VERSION "HNPBNYYYYYYYYYYYYYYYYYYYYYYYYYYYNNNNNNNNNN/4/%%%/4/'%**4NNN///"
NS_ :

BS_:

BU_: BDC546 imc_BUSFX_2_133754 Sender__XXX WC HC0 HC1 HC2 HC3 Xsens_Sensor

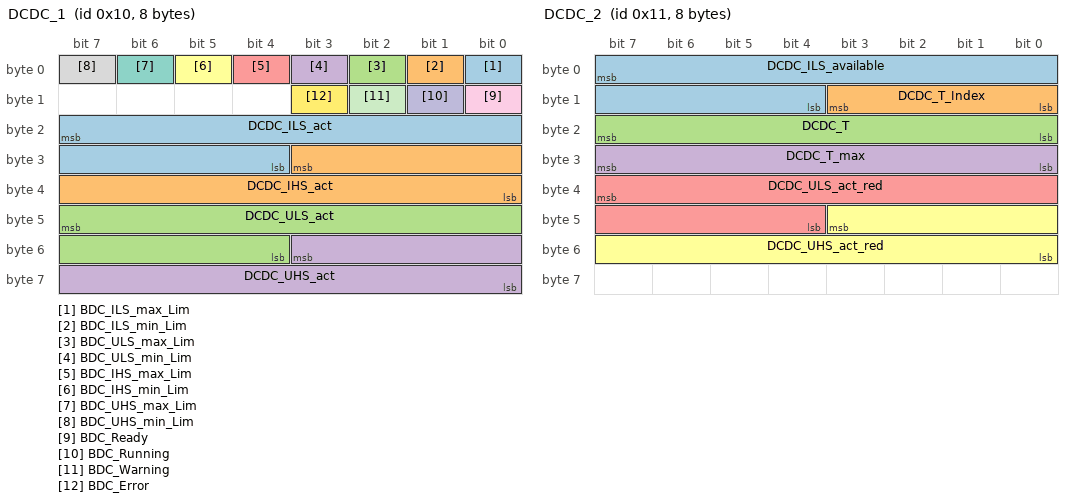
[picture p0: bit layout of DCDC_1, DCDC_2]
BO_ 16 DCDC_1: 8 BDC546
 SG_ BDC_ILS_max_Lim : 0|1@1+ (1,0) [0|1] ""  imc_BUSFX_2_133754
 SG_ BDC_ILS_min_Lim : 1|1@1+ (1,0) [0|1] ""  imc_BUSFX_2_133754
 SG_ BDC_ULS_max_Lim : 2|1@1+ (1,0) [0|1] ""  imc_BUSFX_2_133754
 SG_ BDC_ULS_min_Lim : 3|1@1+ (1,0) [0|1] ""  imc_BUSFX_2_133754
 SG_ BDC_IHS_max_Lim : 4|1@1+ (1,0) [0|1] ""  imc_BUSFX_2_133754
 SG_ BDC_IHS_min_Lim : 5|1@1+ (1,0) [0|1] ""  imc_BUSFX_2_133754
 SG_ BDC_UHS_max_Lim : 6|1@1+ (1,0) [0|1] ""  imc_BUSFX_2_133754
 SG_ BDC_UHS_min_Lim : 7|1@1+ (1,0) [0|1] ""  imc_BUSFX_2_133754
 SG_ BDC_Ready : 8|1@1+ (1,0) [0|1] ""  imc_BUSFX_2_133754
 SG_ BDC_Running : 9|1@1+ (1,0) [0|1] ""  imc_BUSFX_2_133754
 SG_ BDC_Warning : 10|1@1+ (1,0) [0|1] ""  imc_BUSFX_2_133754
 SG_ BDC_Error : 11|1@1+ (1,0) [0|1] ""  imc_BUSFX_2_133754
 SG_ DCDC_ILS_act : 23|12@0+ (2.500000000E-1,-5.120000000E+2) [-5.120000000E+2|5.117500000E+2] "A"  imc_BUSFX_2_133754
 SG_ DCDC_IHS_act : 27|12@0+ (2.500000000E-1,-5.120000000E+2) [-5.120000000E+2|5.117500000E+2] "A"  imc_BUSFX_2_133754
 SG_ DCDC_ULS_act : 47|12@0+ (2.500000000E-1,0.000000000E+0) [0.000000000E+0|1.023750000E+3] "V"  imc_BUSFX_2_133754
 SG_ DCDC_UHS_act : 51|12@0+ (2.500000000E-1,0.000000000E+0) [0.000000000E+0|1.023750000E+3] "V"  imc_BUSFX_2_133754

BO_ 17 DCDC_2: 8 BDC546
 SG_ DCDC_ILS_available : 7|12@0+ (2.500000000E-1,0.000000000E+0) [0.000000000E+0|1.023750000E+3] "A"  imc_BUSFX_2_133754
 SG_ DCDC_T_Index : 11|4@0+ (1.000000000E+0,0.000000000E+0) [0.000000000E+0|1.500000000E+1] ""  imc_BUSFX_2_133754
 SG_ DCDC_T : 23|8@0+ (1.000000000E+0,-4.000000000E+1) [-4.000000000E+1|2.150000000E+2] "C"  imc_BUSFX_2_133754
 SG_ DCDC_T_max : 31|8@0+ (1.000000000E+0,-4.000000000E+1) [-4.000000000E+1|2.150000000E+2] "C"  imc_BUSFX_2_133754
 SG_ DCDC_ULS_act_red : 39|12@0+ (2.500000000E-1,0.000000000E+0) [0.000000000E+0|1.023750000E+3] "V"  imc_BUSFX_2_133754
 SG_ DCDC_UHS_act_red : 43|12@0+ (2.500000000E-1,0.000000000E+0) [0.000000000E+0|1.023750000E+3] "V"  imc_BUSFX_2_133754

BO_ 18 DCDC_3: 8 BDC546
 SG_ BDC_Err_RedNegLS : 0|1@1+ (1,0) [0|1] ""  imc_BUSFX_2_133754
 SG_ BDC_Err_RedPosLS : 1|1@1+ (1,0) [0|1] ""  imc_BUSFX_2_133754
 SG_ BDC_Err_PyroMC : 2|1@1+ (1,0) [0|1] ""  imc_BUSFX_2_133754
 SG_ BDC_Err_TempSens : 8|1@1+ (1,0) [0|1] ""  imc_BUSFX_2_133754
 SG_ BDC_Err_Interlock : 9|1@1+ (1,0) [0|1] ""  imc_BUSFX_2_133754
 SG_ BDC_Err_ISensLS : 10|1@1+ (1,0) [0|1] ""  imc_BUSFX_2_133754
 SG_ BDC_Err_ISensHS : 11|1@1+ (1,0) [0|1] ""  imc_BUSFX_2_133754
 SG_ BDC_Err_BDCMode : 12|1@1+ (1,0) [0|1] ""  imc_BUSFX_2_133754
 SG_ BDC_Err_IHS2ILS : 13|1@1+ (1,0) [0|1] ""  imc_BUSFX_2_133754
 SG_ BDC_Err_RedNegHS : 14|1@1+ (1,0) [0|1] ""  imc_BUSFX_2_133754
 SG_ BDC_Err_RedPosHS : 15|1@1+ (1,0) [0|1] ""  imc_BUSFX_2_133754
 SG_ BDC_Err_Timeout_Recv3 : 19|1@1+ (1,0) [0|1] ""  imc_BUSFX_2_133754
 SG_ BDC_Err_Timeout_Recv2 : 20|1@1+ (1,0) [0|1] ""  imc_BUSFX_2_133754
 SG_ BDC_Err_Timeout_Recv1 : 21|1@1+ (1,0) [0|1] ""  imc_BUSFX_2_133754
 SG_ BDC_Err_CANValue : 22|1@1+ (1,0) [0|1] ""  imc_BUSFX_2_133754
 SG_ BDC_Err_IntSupply : 23|1@1+ (1,0) [0|1] ""  imc_BUSFX_2_133754
 SG_ BDC_Err_FPGA : 3|1@1+ (1,0) [0|1] ""  imc_BUSFX_2_133754
 SG_ BDC_Err_NVSRam : 4|1@1+ (1,0) [0|1] ""  imc_BUSFX_2_133754
 SG_ BDC_Err_Flash : 5|1@1+ (1,0) [0|1] ""  imc_BUSFX_2_133754
 SG_ BDC_Err_EEProm : 6|1@1+ (1,0) [0|1] ""  imc_BUSFX_2_133754
 SG_ BDC_Err_HW_FPGA_Ver : 7|1@1+ (1,0) [0|1] ""  imc_BUSFX_2_133754
 SG_ BDC_Err_CANTx : 16|1@1+ (1,0) [0|1] ""  imc_BUSFX_2_133754
 SG_ BDC_Err_CANRx : 17|1@1+ (1,0) [0|1] ""  imc_BUSFX_2_133754
 SG_ BDC_Err_CANOff : 18|1@1+ (1,0) [0|1] ""  imc_BUSFX_2_133754
 SG_ BDC_Err_OvltSky : 29|1@1+ (1,0) [0|1] ""  imc_BUSFX_2_133754
 SG_ BDC_Err_OvltLS : 30|1@1+ (1,0) [0|1] ""  imc_BUSFX_2_133754
 SG_ BDC_Err_OvltHS : 31|1@1+ (1,0) [0|1] ""  imc_BUSFX_2_133754
 SG_ BDC_War_TempIndD : 32|1@1+ (1,0) [0|1] ""  imc_BUSFX_2_133754
 SG_ BDC_War_TempIndC : 33|1@1+ (1,0) [0|1] ""  imc_BUSFX_2_133754
 SG_ BDC_War_TempIndB : 34|1@1+ (1,0) [0|1] ""  imc_BUSFX_2_133754
 SG_ BDC_War_TempIndA : 35|1@1+ (1,0) [0|1] ""  imc_BUSFX_2_133754
 SG_ BDC_War_Reset : 36|1@1+ (1,0) [0|1] ""  imc_BUSFX_2_133754
 SG_ BDC_War_IMax : 37|1@1+ (1,0) [0|1] ""  imc_BUSFX_2_133754
 SG_ BDC_War_Watchdog : 38|1@1+ (1,0) [0|1] ""  imc_BUSFX_2_133754
 SG_ BDC_War_TempL2x : 45|1@1+ (1,0) [0|1] ""  imc_BUSFX_2_133754
 SG_ BDC_War_TempL1y : 46|1@1+ (1,0) [0|1] ""  imc_BUSFX_2_133754
 SG_ BDC_War_TempL1x : 47|1@1+ (1,0) [0|1] ""  imc_BUSFX_2_133754
 SG_ BDC_Err_FPGA_NVM : 28|1@1+ (1,0) [0|1] ""  imc_BUSFX_2_133754
 SG_ BDC_War_TempL4y : 40|1@1+ (1,0) [0|1] ""  imc_BUSFX_2_133754
 SG_ BDC_War_TempL4x : 41|1@1+ (1,0) [0|1] ""  imc_BUSFX_2_133754
 SG_ BDC_War_TempL3y : 42|1@1+ (1,0) [0|1] ""  imc_BUSFX_2_133754
 SG_ BDC_War_TempL3x : 43|1@1+ (1,0) [0|1] ""  imc_BUSFX_2_133754
 SG_ BDC_War_TempL2y : 44|1@1+ (1,0) [0|1] ""  imc_BUSFX_2_133754
 SG_ BDC_War_HSOvervoltage : 48|1@1+ (1,0) [0|1] ""  imc_BUSFX_2_133754
 SG_ BDC_War_NoIntSupply : 49|1@1+ (1,0) [0|1] ""  imc_BUSFX_2_133754
 SG_ BDC_War_NoHV_UHS : 50|1@1+ (1,0) [0|1] ""  imc_BUSFX_2_133754
 SG_ BDC_War_WrongFPGA : 51|1@1+ (1,0) [0|1] ""  imc_BUSFX_2_133754
 SG_ BDC_War_WrongHW : 52|1@1+ (1,0) [0|1] ""  imc_BUSFX_2_133754
 SG_ BDC_War_PyroVCneg : 53|1@1+ (1,0) [0|1] ""  imc_BUSFX_2_133754
 SG_ BDC_War_PyroVCpos : 54|1@1+ (1,0) [0|1] ""  imc_BUSFX_2_133754
 SG_ BDC_War_Discharge : 55|1@1+ (1,0) [0|1] ""  imc_BUSFX_2_133754
 SG_ BDC_War_CAN_Timeout : 62|1@1+ (1,0) [0|1] ""  imc_BUSFX_2_133754
 SG_ BDC_War_LSOvervoltage : 63|1@1+ (1,0) [0|1] ""  imc_BUSFX_2_133754

BO_ 19 DCDC_4: 8 BDC546
 SG_ BDC_FPGA_SsErr0 : 0|1@1+ (1,0) [0|1] ""  imc_BUSFX_2_133754
 SG_ BDC_FPGA_SsErr1 : 1|1@1+ (1,0) [0|1] ""  imc_BUSFX_2_133754
 SG_ BDC_FPGA_SsErr2 : 2|1@1+ (1,0) [0|1] ""  imc_BUSFX_2_133754
 SG_ BDC_FPGA_SsErr3 : 3|1@1+ (1,0) [0|1] ""  imc_BUSFX_2_133754
 SG_ BDC_FPGA_SsErr4 : 4|1@1+ (1,0) [0|1] ""  imc_BUSFX_2_133754
 SG_ BDC_FPGA_SsErr5 : 5|1@1+ (1,0) [0|1] ""  imc_BUSFX_2_133754
 SG_ BDC_FPGA_SsErr6 : 6|1@1+ (1,0) [0|1] ""  imc_BUSFX_2_133754
 SG_ BDC_FPGA_SsErr7 : 7|1@1+ (1,0) [0|1] ""  imc_BUSFX_2_133754
 SG_ BDC_FPGA_ILmaxErr0 : 8|1@1+ (1,0) [0|1] ""  imc_BUSFX_2_133754
 SG_ BDC_FPGA_ILmaxErr1 : 9|1@1+ (1,0) [0|1] ""  imc_BUSFX_2_133754
 SG_ BDC_FPGA_ILmaxErr2 : 10|1@1+ (1,0) [0|1] ""  imc_BUSFX_2_133754
 SG_ BDC_FPGA_ILmaxErr3 : 11|1@1+ (1,0) [0|1] ""  imc_BUSFX_2_133754
 SG_ BDC_FPGA_ILmaxErr4 : 12|1@1+ (1,0) [0|1] ""  imc_BUSFX_2_133754
 SG_ BDC_FPGA_ILmaxErr5 : 13|1@1+ (1,0) [0|1] ""  imc_BUSFX_2_133754
 SG_ BDC_FPGA_ILmaxErr6 : 14|1@1+ (1,0) [0|1] ""  imc_BUSFX_2_133754
 SG_ BDC_FPGA_ILmaxErr7 : 15|1@1+ (1,0) [0|1] ""  imc_BUSFX_2_133754
 SG_ BDC_FPGA_UBmaxErr : 16|1@1+ (1,0) [0|1] ""  imc_BUSFX_2_133754
 SG_ BDC_FPGA_UA1maxErr : 17|1@1+ (1,0) [0|1] ""  imc_BUSFX_2_133754
 SG_ BDC_FPGA_U15VmaxErr : 18|1@1+ (1,0) [0|1] ""  imc_BUSFX_2_133754
 SG_ BDC_FPGA_IBmaxErr : 23|1@1+ (1,0) [0|1] ""  imc_BUSFX_2_133754
 SG_ BDC_FPGA_GenRglPer : 24|1@1+ (1,0) [0|1] ""  imc_BUSFX_2_133754
 SG_ BDC_FPGA_IllegalAccess : 27|1@1+ (1,0) [0|1] ""  imc_BUSFX_2_133754
 SG_ BDC_FPGA_Hw_Err0 : 28|1@1+ (1,0) [0|1] ""  imc_BUSFX_2_133754
 SG_ BDC_FPGA_Hw_Err1 : 29|1@1+ (1,0) [0|1] ""  imc_BUSFX_2_133754
 SG_ DCDC_FPGA_IntStatUnused3 : 22|4@0- (1.000000000E+0,0.000000000E+0) [-8.000000000E+0|7.000000000E+0] ""  imc_BUSFX_2_133754
 SG_ DCDC_FPGA_IntStatUnused1 : 26|2@0- (1.000000000E+0,0.000000000E+0) [-2.000000000E+0|1.000000000E+0] ""  imc_BUSFX_2_133754
 SG_ DCDC_FPGA_IntStatUnused2 : 31|2@0- (1.000000000E+0,0.000000000E+0) [-2.000000000E+0|1.000000000E+0] ""  imc_BUSFX_2_133754
 SG_ DCDC_CAN_RXCNT : 39|8@0+ (1.000000000E+0,0.000000000E+0) [0.000000000E+0|2.550000000E+2] ""  imc_BUSFX_2_133754
 SG_ DCDC_CAN_TXCNT : 47|8@0+ (1.000000000E+0,0.000000000E+0) [0.000000000E+0|2.550000000E+2] ""  imc_BUSFX_2_133754
 SG_ DCDC_SG_IL_max : 55|16@0+ (3.125000000E-2,-1.024000000E+3) [-1.024000000E+3|1.023968750E+3] "A"  imc_BUSFX_2_133754

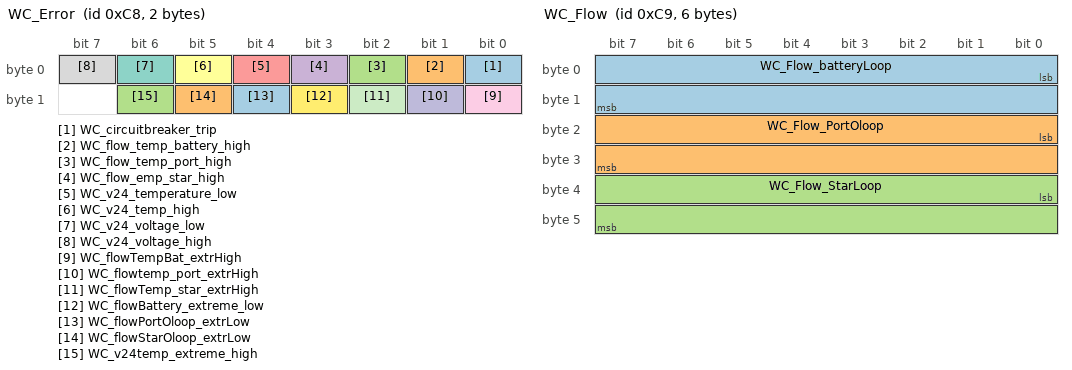
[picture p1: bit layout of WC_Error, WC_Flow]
BO_ 200 WC_Error: 2 Sender__XXX
 SG_ WC_circuitbreaker_trip : 0|1@1+ (1,0) [0|1] ""  imc_BUSFX_2_133754
 SG_ WC_flow_temp_battery_high : 1|1@1+ (1,0) [0|1] ""  imc_BUSFX_2_133754
 SG_ WC_flow_temp_port_high : 2|1@1+ (1,0) [0|1] ""  imc_BUSFX_2_133754
 SG_ WC_flow_emp_star_high : 3|1@1+ (1,0) [0|1] ""  imc_BUSFX_2_133754
 SG_ WC_v24_temperature_low : 4|1@1+ (1,0) [0|1] ""  imc_BUSFX_2_133754
 SG_ WC_v24_temp_high : 5|1@1+ (1,0) [0|1] ""  imc_BUSFX_2_133754
 SG_ WC_v24_voltage_low : 6|1@1+ (1,0) [0|1] ""  imc_BUSFX_2_133754
 SG_ WC_v24_voltage_high : 7|1@1+ (1,0) [0|1] ""  imc_BUSFX_2_133754
 SG_ WC_flowTempBat_extrHigh : 8|1@1+ (1,0) [0|1] ""  imc_BUSFX_2_133754
 SG_ WC_flowtemp_port_extrHigh : 9|1@1+ (1,0) [0|1] ""  imc_BUSFX_2_133754
 SG_ WC_flowTemp_star_extrHigh : 10|1@1+ (1,0) [0|1] ""  imc_BUSFX_2_133754
 SG_ WC_flowBattery_extreme_low : 11|1@1+ (1,0) [0|1] ""  imc_BUSFX_2_133754
 SG_ WC_flowPortOloop_extrLow : 12|1@1+ (1,0) [0|1] ""  imc_BUSFX_2_133754
 SG_ WC_flowStarOloop_extrLow : 13|1@1+ (1,0) [0|1] ""  imc_BUSFX_2_133754
 SG_ WC_v24temp_extreme_high : 14|1@1+ (1,0) [0|1] ""  imc_BUSFX_2_133754

BO_ 201 WC_Flow: 6 Sender__XXX
 SG_ WC_Flow_batteryLoop : 0|16@1+ (7.629510948E-4,0.000000000E+0) [0.000000000E+0|5.000000000E+1] "L/min"  imc_BUSFX_2_133754
 SG_ WC_Flow_PortOloop : 16|16@1+ (7.629510948E-4,0.000000000E+0) [0.000000000E+0|5.000000000E+1] "L/min"  imc_BUSFX_2_133754
 SG_ WC_Flow_StarLoop : 32|16@1+ (7.629510948E-4,0.000000000E+0) [0.000000000E+0|5.000000000E+1] "L/min"  imc_BUSFX_2_133754

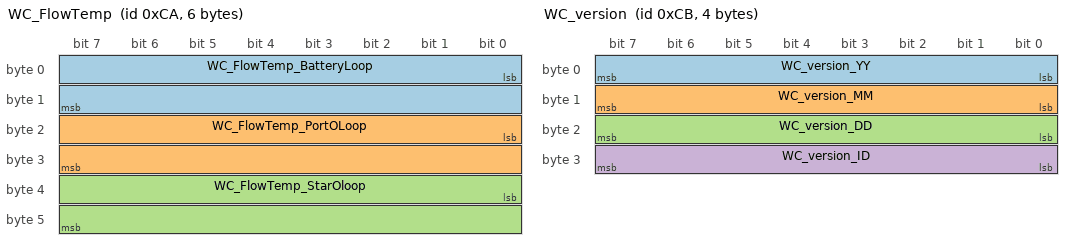
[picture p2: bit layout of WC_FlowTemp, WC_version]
BO_ 202 WC_FlowTemp: 6 Sender__XXX
 SG_ WC_FlowTemp_BatteryLoop : 0|16@1+ (2.288853285E-3,0.000000000E+0) [0.000000000E+0|1.500000000E+2] "C"  imc_BUSFX_2_133754
 SG_ WC_FlowTemp_PortOLoop : 16|16@1+ (2.288853285E-3,0.000000000E+0) [0.000000000E+0|1.500000000E+2] "C"  imc_BUSFX_2_133754
 SG_ WC_FlowTemp_StarOloop : 32|16@1+ (2.288853285E-3,0.000000000E+0) [0.000000000E+0|1.500000000E+2] "C"  imc_BUSFX_2_133754

BO_ 203 WC_version: 4 WC
 SG_ WC_version_YY : 0|8@1- (1.000000000E+0,0.000000000E+0) [-1.280000000E+2|1.270000000E+2] ""  imc_BUSFX_2_133754
 SG_ WC_version_MM : 8|8@1- (1.000000000E+0,0.000000000E+0) [-1.280000000E+2|1.270000000E+2] ""  imc_BUSFX_2_133754
 SG_ WC_version_DD : 16|8@1- (1.000000000E+0,0.000000000E+0) [-1.280000000E+2|1.270000000E+2] ""  imc_BUSFX_2_133754
 SG_ WC_version_ID : 24|8@1- (1.000000000E+0,0.000000000E+0) [-1.280000000E+2|1.270000000E+2] ""  imc_BUSFX_2_133754

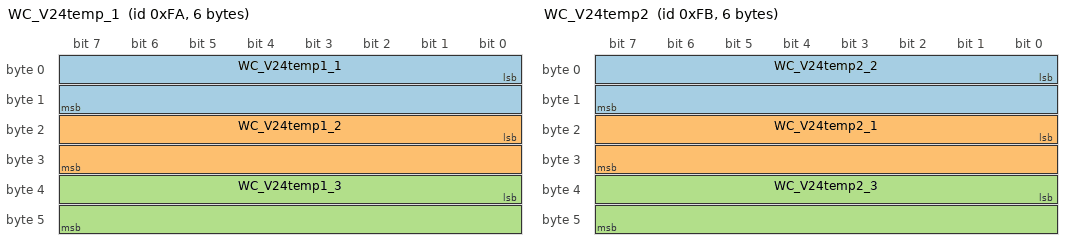
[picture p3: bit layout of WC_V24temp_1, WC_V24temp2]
BO_ 250 WC_V24temp_1: 6 Sender__XXX
 SG_ WC_V24temp1_1 : 0|16@1+ (2.288853280E-3,0.000000000E+0) [0.000000000E+0|1.499999997E+2] "C"  imc_BUSFX_2_133754
 SG_ WC_V24temp1_2 : 16|16@1+ (2.288853280E-3,0.000000000E+0) [0.000000000E+0|1.499999997E+2] "C"  imc_BUSFX_2_133754
 SG_ WC_V24temp1_3 : 32|16@1+ (2.288853280E-3,0.000000000E+0) [0.000000000E+0|1.499999997E+2] "C"  imc_BUSFX_2_133754

BO_ 251 WC_V24temp2: 6 Sender__XXX
 SG_ WC_V24temp2_2 : 0|16@1- (2.288853280E-3,0.000000000E+0) [-7.500114428E+1|7.499885543E+1] "C"  imc_BUSFX_2_133754
 SG_ WC_V24temp2_1 : 16|16@1- (2.288853280E-3,0.000000000E+0) [-7.500114428E+1|7.499885543E+1] "C"  imc_BUSFX_2_133754
 SG_ WC_V24temp2_3 : 32|16@1- (2.288853280E-3,0.000000000E+0) [-7.500114428E+1|7.499885543E+1] "C"  imc_BUSFX_2_133754

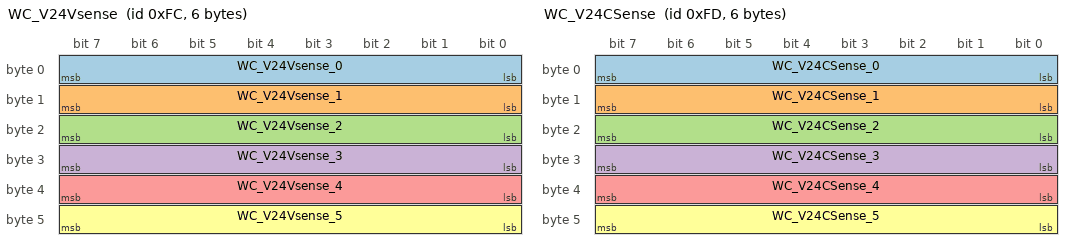
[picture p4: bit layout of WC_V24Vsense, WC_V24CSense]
BO_ 252 WC_V24Vsense: 6 Sender__XXX
 SG_ WC_V24Vsense_0 : 0|8@1+ (1.176470588E-1,0.000000000E+0) [0.000000000E+0|2.999999999E+1] "V"  imc_BUSFX_2_133754
 SG_ WC_V24Vsense_1 : 8|8@1+ (1.176470588E-1,0.000000000E+0) [0.000000000E+0|2.999999999E+1] "V"  imc_BUSFX_2_133754
 SG_ WC_V24Vsense_2 : 16|8@1+ (1.176470588E-1,0.000000000E+0) [0.000000000E+0|2.999999999E+1] "V"  imc_BUSFX_2_133754
 SG_ WC_V24Vsense_3 : 24|8@1+ (1.176470588E-1,0.000000000E+0) [0.000000000E+0|2.999999999E+1] "V"  imc_BUSFX_2_133754
 SG_ WC_V24Vsense_4 : 32|8@1+ (1.176470588E-1,0.000000000E+0) [0.000000000E+0|2.999999999E+1] "V"  imc_BUSFX_2_133754
 SG_ WC_V24Vsense_5 : 40|8@1+ (1.176470588E-1,0.000000000E+0) [0.000000000E+0|2.999999999E+1] "V"  imc_BUSFX_2_133754

BO_ 253 WC_V24CSense: 6 Sender__XXX
 SG_ WC_V24CSense_0 : 0|8@1+ (9.803921568E-2,0.000000000E+0) [0.000000000E+0|2.500000000E+1] "A"  imc_BUSFX_2_133754
 SG_ WC_V24CSense_1 : 8|8@1+ (9.803921568E-2,0.000000000E+0) [0.000000000E+0|2.500000000E+1] "A"  imc_BUSFX_2_133754
 SG_ WC_V24CSense_2 : 16|8@1+ (9.803921568E-2,0.000000000E+0) [0.000000000E+0|2.500000000E+1] "A"  imc_BUSFX_2_133754
 SG_ WC_V24CSense_3 : 24|8@1- (9.803921568E-2,0.000000000E+0) [-1.254901961E+1|1.245098039E+1] "A"  imc_BUSFX_2_133754
 SG_ WC_V24CSense_4 : 32|8@1- (9.803921568E-2,0.000000000E+0) [-1.254901961E+1|1.245098039E+1] "A"  imc_BUSFX_2_133754
 SG_ WC_V24CSense_5 : 40|8@1- (9.803921568E-2,0.000000000E+0) [-1.254901961E+1|1.245098039E+1] "A"  imc_BUSFX_2_133754

BO_ 300 EMS_Error: 8 Sender__XXX
 SG_ EMSFE_cellV_extrLow : 0|1@1+ (1,0) [0|1] ""  imc_BUSFX_2_133754
 SG_ EMSHE_cellV_extrHigh : 1|1@1+ (1,0) [0|1] ""  imc_BUSFX_2_133754
 SG_ EMSFE_WC_nc : 2|1@1+ (1,0) [0|1] ""  imc_BUSFX_2_133754
 SG_ EMSFE_steer_nc : 3|1@1+ (1,0) [0|1] ""  imc_BUSFX_2_133754
 SG_ EMSFE_dashboard_nc : 4|1@1+ (1,0) [0|1] ""  imc_BUSFX_2_133754
 SG_ EMSFE_H2sens_nc : 5|1@1+ (1,0) [0|1] ""  imc_BUSFX_2_133754
 SG_ EMSFE_hydrogenPerc_high : 6|1@1+ (1,0) [0|1] ""  imc_BUSFX_2_133754
 SG_ EMSFE_CBtrip : 7|1@1+ (1,0) [0|1] ""  imc_BUSFX_2_133754
 SG_ EMSFE_BMSslave_nc : 14|1@1+ (1,0) [0|1] ""  imc_BUSFX_2_133754
 SG_ EMSHE_flowPortOloop_extrLow : 16|1@1+ (1,0) [0|1] ""  imc_BUSFX_2_133754
 SG_ EMSHE_flowStarOloop_eLow : 17|1@1+ (1,0) [0|1] ""  imc_BUSFX_2_133754
 SG_ EMSHE_FlowDCDC_extLow : 18|1@1+ (1,0) [0|1] ""  imc_BUSFX_2_133754
 SG_ EMSHE_flowMotor_extLow : 19|1@1+ (1,0) [0|1] ""  imc_BUSFX_2_133754
 SG_ EMSFE_NumbCellsLow : 20|1@1+ (1,0) [0|1] ""  imc_BUSFX_2_133754
 SG_ EMSHE_motorT_extrHigh : 21|1@1+ (1,0) [0|1] ""  imc_BUSFX_2_133754
 SG_ EMSFE_isolation : 22|1@1+ (1,0) [0|1] ""  imc_BUSFX_2_133754
 SG_ EMSFE_EmerLoop : 12|1@1+ (1,0) [0|1] ""  imc_BUSFX_2_133754
 SG_ EMSFE_MotorCont_nc : 13|1@1+ (1,0) [0|1] ""  imc_BUSFX_2_133754
 SG_ EMSFE_BMSmaster_nc : 15|1@1+ (1,0) [0|1] ""  imc_BUSFX_2_133754
 SG_ EMS_cellVoltage_high : 39|1@1+ (1,0) [0|1] ""  imc_BUSFX_2_133754
 SG_ EMS_overcurrent : 40|1@1+ (1,0) [0|1] ""  imc_BUSFX_2_133754
 SG_ EMS_motorTemp_high : 41|1@1+ (1,0) [0|1] ""  imc_BUSFX_2_133754
 SG_ EMS_TempBattLoop_high : 42|1@1+ (1,0) [0|1] ""  imc_BUSFX_2_133754
 SG_ EMS_TempPortOloop_high : 43|1@1+ (1,0) [0|1] ""  imc_BUSFX_2_133754
 SG_ EMS_tempStarOloop_high : 44|1@1+ (1,0) [0|1] ""  imc_BUSFX_2_133754
 SG_ EMS_tempDCDCloop_high : 45|1@1+ (1,0) [0|1] ""  imc_BUSFX_2_133754
 SG_ EMSHE_tankpressure_low : 46|1@1+ (1,0) [0|1] ""  imc_BUSFX_2_133754
 SG_ EMS_tempMotorLoop_high : 47|1@1+ (1,0) [0|1] ""  imc_BUSFX_2_133754
 SG_ EMS_FATAL_ERROR : 48|1@1+ (1,0) [0|1] ""  imc_BUSFX_2_133754
 SG_ EMS_TankTemp_high : 49|1@1+ (1,0) [0|1] ""  imc_BUSFX_2_133754
 SG_ EMS_HARBOUR_ERROR : 50|1@1+ (1,0) [0|1] ""  imc_BUSFX_2_133754
 SG_ EMSFE_cellT_extrHigh : 23|1@1+ (1,0) [0|1] ""  imc_BUSFX_2_133754
 SG_ EMSHE_TbattLoop_extrHigh : 24|1@1+ (1,0) [0|1] ""  imc_BUSFX_2_133754
 SG_ EMSHE_TportOloop_extrHigh : 25|1@1+ (1,0) [0|1] ""  imc_BUSFX_2_133754
 SG_ EMSHE_TStarOloopExtrHigh : 26|1@1+ (1,0) [0|1] ""  imc_BUSFX_2_133754
 SG_ EMSHE_tDCDCloopExtrHigh : 27|1@1+ (1,0) [0|1] ""  imc_BUSFX_2_133754
 SG_ EMSHE_DCDC_nc : 28|1@1+ (1,0) [0|1] ""  imc_BUSFX_2_133754
 SG_ EMSHE_TmotorLoop_extrHigh : 29|1@1+ (1,0) [0|1] ""  imc_BUSFX_2_133754
 SG_ EMSHE_fFuelcell_nc : 30|1@1+ (1,0) [0|1] ""  imc_BUSFX_2_133754
 SG_ EMSHE_flowBat_extrLow : 31|1@1+ (1,0) [0|1] ""  imc_BUSFX_2_133754
 SG_ EMS_v24_tempLow : 32|1@1+ (1,0) [0|1] ""  imc_BUSFX_2_133754
 SG_ EMS_v24temp_high : 33|1@1+ (1,0) [0|1] ""  imc_BUSFX_2_133754
 SG_ EMS_v24voltage_low : 34|1@1+ (1,0) [0|1] ""  imc_BUSFX_2_133754
 SG_ EMS_v24voltage_high : 35|1@1+ (1,0) [0|1] ""  imc_BUSFX_2_133754
 SG_ EMS_cellTemp_low : 36|1@1+ (1,0) [0|1] ""  imc_BUSFX_2_133754
 SG_ EMS_cellTemp_high : 37|1@1+ (1,0) [0|1] ""  imc_BUSFX_2_133754
 SG_ EMS_cellVoltage_low : 38|1@1+ (1,0) [0|1] ""  imc_BUSFX_2_133754
 SG_ EMS_LastHarbourError : 56|4@1+ (1.000000000E+0,0.000000000E+0) [0.000000000E+0|1.500000000E+1] "0"  imc_BUSFX_2_133754
 SG_ EMS_LastFatalError : 60|4@1+ (1.000000000E+0,0.000000000E+0) [0.000000000E+0|1.500000000E+1] ""  imc_BUSFX_2_133754

BO_ 301 EMS_FlowTemp: 4 Sender__XXX
 SG_ EMS_FlowTemp_motorLoop : 7|16@0+ (2.288853285E-3,0.000000000E+0) [0.000000000E+0|1.500000000E+2] "C"  imc_BUSFX_2_133754
 SG_ EMS_FlowTemp_dcdc : 23|16@0+ (2.288853285E-3,0.000000000E+0) [0.000000000E+0|1.500000000E+2] "C"  imc_BUSFX_2_133754

BO_ 302 EMS_flow: 6 Sender__XXX
 SG_ EMS_flow_dcdc : 0|16@1+ (7.629510948E-4,0.000000000E+0) [0.000000000E+0|5.000000000E+1] "L/min"  imc_BUSFX_2_133754
 SG_ EMS_flow_motorLoop : 16|16@1+ (7.629510948E-4,0.000000000E+0) [0.000000000E+0|5.000000000E+1] "L/min"  imc_BUSFX_2_133754

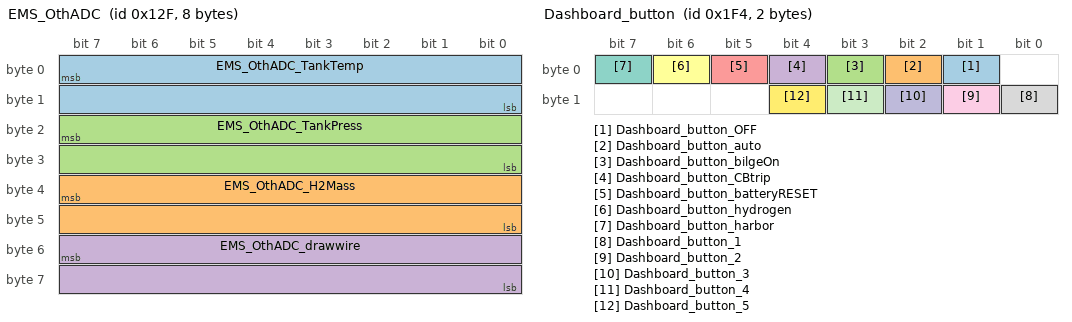
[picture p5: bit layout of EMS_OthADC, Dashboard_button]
BO_ 303 EMS_OthADC: 8 Sender__XXX
 SG_ EMS_OthADC_TankTemp : 7|16@0- (2.288853280E-3,0.000000000E+0) [-7.500114428E+1|7.499885543E+1] "C"  imc_BUSFX_2_133754
 SG_ EMS_OthADC_H2Mass : 39|16@0+ (1.525902100E-4,0.000000000E+0) [0.000000000E+0|9.999999412E+0] "KG"  imc_BUSFX_2_133754
 SG_ EMS_OthADC_TankPress : 23|16@0+ (6.836041810E-3,0.000000000E+0) [0.000000000E+0|4.480000000E+2] "Bar"  imc_BUSFX_2_133754
 SG_ EMS_OthADC_drawwire : 55|16@0- (1.525902000E-5,0.000000000E+0) [-5.000075674E-1|4.999923083E-1] "degree"  imc_BUSFX_2_133754

BO_ 304 EMS_isometer: 2 Sender__XXX
 SG_ EMS_isometer_freq : 0|8@1+ (1.000000000E+0,0.000000000E+0) [0.000000000E+0|2.550000000E+2] "Hz"  imc_BUSFX_2_133754
 SG_ EMS_isometer_DutyCycle : 8|8@1+ (3.921568627E-3,0.000000000E+0) [0.000000000E+0|9.999999999E-1] "%"  imc_BUSFX_2_133754

BO_ 305 EMS_Status_Message: 8 Sender__XXX
 SG_ EMS_Config_Tank : 1|1@1+ (1,0) [0|1] ""  imc_BUSFX_2_133754
 SG_ EMS_Status_MotorStarted : 15|1@1+ (1,0) [0|1] ""  imc_BUSFX_2_133754

BO_ 306 EMS_send_rpm: 3 Sender__XXX
 SG_ EMS_send_drivereverse : 0|8@1+ (1.000000000E+0,0.000000000E+0) [0.000000000E+0|2.550000000E+2] ""  imc_BUSFX_2_133754
 SG_ EMS_send_rpm : 8|16@1- (1.220740379E-1,0.000000000E+0) [-4.000122074E+3|4.000000000E+3] ""  imc_BUSFX_2_133754

BO_ 500 Dashboard_button: 2 Sender__XXX
 SG_ Dashboard_button_OFF : 1|1@1+ (1,0) [0|1] ""  imc_BUSFX_2_133754
 SG_ Dashboard_button_auto : 2|1@1+ (1,0) [0|1] ""  imc_BUSFX_2_133754
 SG_ Dashboard_button_bilgeOn : 3|1@1+ (1,0) [0|1] ""  imc_BUSFX_2_133754
 SG_ Dashboard_button_CBtrip : 4|1@1+ (1,0) [0|1] ""  imc_BUSFX_2_133754
 SG_ Dashboard_button_batteryRESET : 5|1@1+ (1,0) [0|1] ""  imc_BUSFX_2_133754
 SG_ Dashboard_button_hydrogen : 6|1@1+ (1,0) [0|1] ""  imc_BUSFX_2_133754
 SG_ Dashboard_button_harbor : 7|1@1+ (1,0) [0|1] ""  imc_BUSFX_2_133754
 SG_ Dashboard_button_1 : 8|1@1+ (1,0) [0|1] ""  imc_BUSFX_2_133754
 SG_ Dashboard_button_2 : 9|1@1+ (1,0) [0|1] ""  imc_BUSFX_2_133754
 SG_ Dashboard_button_3 : 10|1@1+ (1,0) [0|1] ""  imc_BUSFX_2_133754
 SG_ Dashboard_button_4 : 11|1@1+ (1,0) [0|1] ""  imc_BUSFX_2_133754
 SG_ Dashboard_button_5 : 12|1@1+ (1,0) [0|1] ""  imc_BUSFX_2_133754

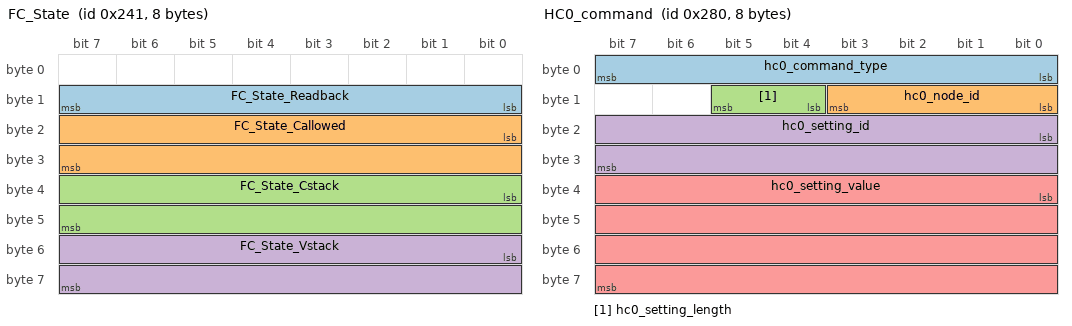
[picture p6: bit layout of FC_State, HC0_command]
BO_ 577 FC_State: 8 Sender__XXX
 SG_ FC_State_Readback : 8|8@1- (1.000000000E+0,0.000000000E+0) [-1.280000000E+2|1.270000000E+2] ""  imc_BUSFX_2_133754
 SG_ FC_State_Callowed : 16|16@1+ (1.000000000E-1,0.000000000E+0) [0.000000000E+0|6.553500000E+3] "A"  imc_BUSFX_2_133754
 SG_ FC_State_Cstack : 32|16@1- (1.000000000E-1,0.000000000E+0) [-3.276800000E+3|3.276700000E+3] "A"  imc_BUSFX_2_133754
 SG_ FC_State_Vstack : 48|16@1+ (1.000000000E-1,0.000000000E+0) [0.000000000E+0|6.553500000E+3] "V"  imc_BUSFX_2_133754

BO_ 640 HC0_command: 8 Sender__XXX
 SG_ hc0_command_type : 0|8@1+ (1.000000000E+0,0.000000000E+0) [0.000000000E+0|2.550000000E+2] ""  imc_BUSFX_2_133754
 SG_ hc0_node_id : 8|4@1+ (1.000000000E+0,0.000000000E+0) [0.000000000E+0|1.500000000E+1] ""  imc_BUSFX_2_133754
 SG_ hc0_setting_length : 12|2@1+ (1.000000000E+0,0.000000000E+0) [0.000000000E+0|3.000000000E+0] ""  imc_BUSFX_2_133754
 SG_ hc0_setting_id : 16|16@1+ (1.000000000E+0,0.000000000E+0) [0.000000000E+0|6.553500000E+4] ""  imc_BUSFX_2_133754
 SG_ hc0_setting_value : 32|32@1+ (1.000000000E+0,0.000000000E+0) [0.000000000E+0|4.294967295E+9] ""  imc_BUSFX_2_133754

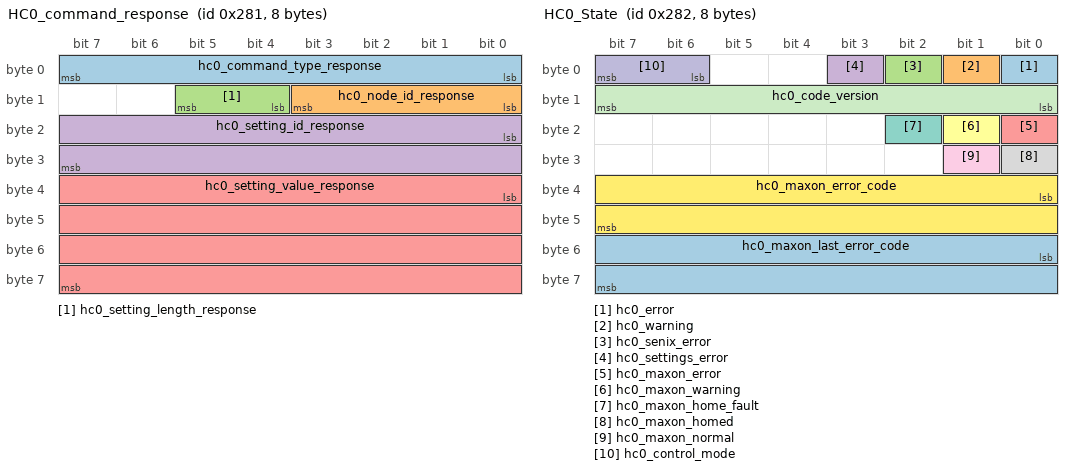
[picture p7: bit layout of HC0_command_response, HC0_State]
BO_ 641 HC0_command_response: 8 HC0
 SG_ hc0_command_type_response : 0|8@1+ (1.000000000E+0,0.000000000E+0) [0.000000000E+0|2.550000000E+2] ""  imc_BUSFX_2_133754
 SG_ hc0_node_id_response : 8|4@1+ (1.000000000E+0,0.000000000E+0) [0.000000000E+0|1.500000000E+1] ""  imc_BUSFX_2_133754
 SG_ hc0_setting_length_response : 12|2@1+ (1.000000000E+0,0.000000000E+0) [0.000000000E+0|3.000000000E+0] ""  imc_BUSFX_2_133754
 SG_ hc0_setting_id_response : 16|16@1+ (1.000000000E+0,0.000000000E+0) [0.000000000E+0|6.553500000E+4] ""  imc_BUSFX_2_133754
 SG_ hc0_setting_value_response : 32|32@1+ (1.000000000E+0,0.000000000E+0) [0.000000000E+0|4.294967295E+9] ""  imc_BUSFX_2_133754

BO_ 642 HC0_State: 8 HC0
 SG_ hc0_error : 0|1@1+ (1,0) [0|1] ""  imc_BUSFX_2_133754
 SG_ hc0_warning : 1|1@1+ (1,0) [0|1] ""  imc_BUSFX_2_133754
 SG_ hc0_senix_error : 2|1@1+ (1,0) [0|1] ""  imc_BUSFX_2_133754
 SG_ hc0_settings_error : 3|1@1+ (1,0) [0|1] ""  imc_BUSFX_2_133754
 SG_ hc0_maxon_error : 16|1@1+ (1,0) [0|1] ""  imc_BUSFX_2_133754
 SG_ hc0_maxon_warning : 17|1@1+ (1,0) [0|1] ""  imc_BUSFX_2_133754
 SG_ hc0_maxon_home_fault : 18|1@1+ (1,0) [0|1] ""  imc_BUSFX_2_133754
 SG_ hc0_maxon_homed : 24|1@1+ (1,0) [0|1] ""  imc_BUSFX_2_133754
 SG_ hc0_maxon_normal : 25|1@1+ (1,0) [0|1] ""  imc_BUSFX_2_133754
 SG_ hc0_control_mode : 6|2@1+ (1.000000000E+0,0.000000000E+0) [0.000000000E+0|3.000000000E+0] ""  imc_BUSFX_2_133754
 SG_ hc0_code_version : 8|8@1+ (1.000000000E+0,0.000000000E+0) [0.000000000E+0|2.550000000E+2] ""  imc_BUSFX_2_133754
 SG_ hc0_maxon_error_code : 32|16@1+ (1.000000000E+0,0.000000000E+0) [0.000000000E+0|6.553500000E+4] ""  imc_BUSFX_2_133754
 SG_ hc0_maxon_last_error_code : 48|16@1+ (1.000000000E+0,0.000000000E+0) [0.000000000E+0|6.553500000E+4] ""  imc_BUSFX_2_133754

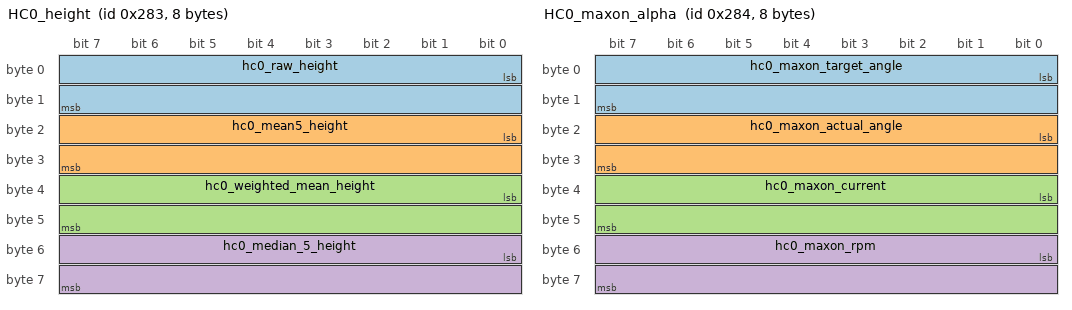
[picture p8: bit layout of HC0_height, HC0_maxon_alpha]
BO_ 643 HC0_height: 8 HC0
 SG_ hc0_raw_height : 0|16@1- (1.000000000E+0,0.000000000E+0) [-3.276800000E+4|3.276700000E+4] "mm"  imc_BUSFX_2_133754
 SG_ hc0_mean5_height : 16|16@1- (1.000000000E+0,0.000000000E+0) [-3.276800000E+4|3.276700000E+4] "mm"  imc_BUSFX_2_133754
 SG_ hc0_weighted_mean_height : 32|16@1- (1.000000000E+0,0.000000000E+0) [-3.276800000E+4|3.276700000E+4] "mm"  imc_BUSFX_2_133754
 SG_ hc0_median_5_height : 48|16@1- (1.000000000E+0,0.000000000E+0) [-3.276800000E+4|3.276700000E+4] "mm"  imc_BUSFX_2_133754

BO_ 644 HC0_maxon_alpha: 8 HC0
 SG_ hc0_maxon_target_angle : 0|16@1- (6.103701900E-4,0.000000000E+0) [-2.000061039E+1|2.000000002E+1] "deg"  imc_BUSFX_2_133754
 SG_ hc0_maxon_actual_angle : 16|16@1- (6.103701900E-4,0.000000000E+0) [-2.000061039E+1|2.000000002E+1] "deg"  imc_BUSFX_2_133754
 SG_ hc0_maxon_current : 32|16@1- (1.000000000E+0,0.000000000E+0) [-3.276800000E+4|3.276700000E+4] "mA"  imc_BUSFX_2_133754
 SG_ hc0_maxon_rpm : 48|16@1- (1.000000000E+0,0.000000000E+0) [-3.276800000E+4|3.276700000E+4] "rpm"  imc_BUSFX_2_133754

BO_ 645 HC0_maxon_position: 8 HC0
 SG_ hc0_maxon_target_position : 0|32@1- (1.000000000E+0,0.000000000E+0) [-2.147483648E+9|2.147483647E+9] "inc"  imc_BUSFX_2_133754
 SG_ hc0_maxon_actual_position : 32|32@1- (1.000000000E+0,0.000000000E+0) [-2.147483648E+9|2.147483647E+9] "inc"  imc_BUSFX_2_133754

BO_ 647 HC0_P_gains: 8 HC0
 SG_ hc0_P_height : 0|32@1- (1.000000000E-5,0.000000000E+0) [-2.147483648E+4|2.147483647E+4] ""  imc_BUSFX_2_133754
 SG_ hc0_P_roll : 32|32@1- (1.000000000E-5,0.000000000E+0) [-2.147483648E+4|2.147483647E+4] ""  imc_BUSFX_2_133754

BO_ 648 HC0_I_gains: 8 HC0
 SG_ hc0_I_height : 0|32@1- (1.000000000E-5,0.000000000E+0) [-2.147483648E+4|2.147483647E+4] ""  imc_BUSFX_2_133754
 SG_ hc0_I_roll : 32|32@1- (1.000000000E-5,0.000000000E+0) [-2.147483648E+4|2.147483647E+4] ""  imc_BUSFX_2_133754

BO_ 649 HC0_D_gains: 8 HC0
 SG_ hc0_D_height : 0|32@1- (1.000000000E-5,0.000000000E+0) [-2.147483648E+4|2.147483647E+4] ""  imc_BUSFX_2_133754
 SG_ hc0_D_roll : 32|32@1- (1.000000000E-5,0.000000000E+0) [-2.147483648E+4|2.147483647E+4] ""  imc_BUSFX_2_133754

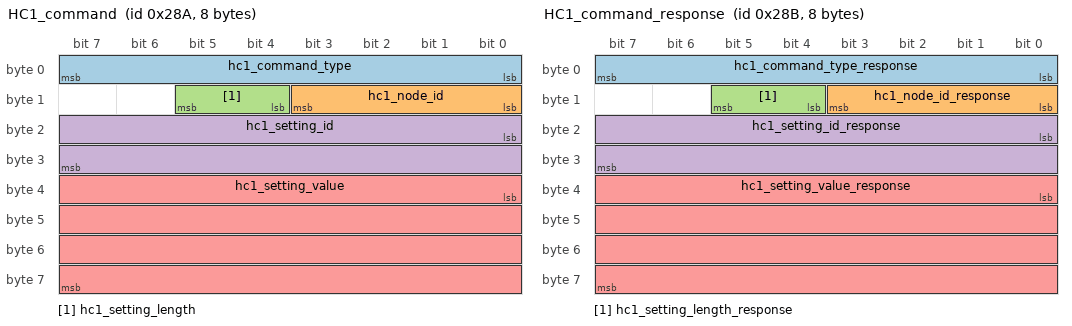
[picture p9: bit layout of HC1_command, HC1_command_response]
BO_ 650 HC1_command: 8 Sender__XXX
 SG_ hc1_command_type : 0|8@1+ (1.000000000E+0,0.000000000E+0) [0.000000000E+0|2.550000000E+2] ""  imc_BUSFX_2_133754
 SG_ hc1_node_id : 8|4@1+ (1.000000000E+0,0.000000000E+0) [0.000000000E+0|1.500000000E+1] ""  imc_BUSFX_2_133754
 SG_ hc1_setting_length : 12|2@1+ (1.000000000E+0,0.000000000E+0) [0.000000000E+0|3.000000000E+0] ""  imc_BUSFX_2_133754
 SG_ hc1_setting_id : 16|16@1+ (1.000000000E+0,0.000000000E+0) [0.000000000E+0|6.553500000E+4] ""  imc_BUSFX_2_133754
 SG_ hc1_setting_value : 32|32@1+ (1.000000000E+0,0.000000000E+0) [0.000000000E+0|4.294967295E+9] ""  imc_BUSFX_2_133754

BO_ 651 HC1_command_response: 8 HC1
 SG_ hc1_command_type_response : 0|8@1+ (1.000000000E+0,0.000000000E+0) [0.000000000E+0|2.550000000E+2] ""  imc_BUSFX_2_133754
 SG_ hc1_node_id_response : 8|4@1+ (1.000000000E+0,0.000000000E+0) [0.000000000E+0|1.500000000E+1] ""  imc_BUSFX_2_133754
 SG_ hc1_setting_length_response : 12|2@1+ (1.000000000E+0,0.000000000E+0) [0.000000000E+0|3.000000000E+0] ""  imc_BUSFX_2_133754
 SG_ hc1_setting_id_response : 16|16@1+ (1.000000000E+0,0.000000000E+0) [0.000000000E+0|6.553500000E+4] ""  imc_BUSFX_2_133754
 SG_ hc1_setting_value_response : 32|32@1+ (1.000000000E+0,0.000000000E+0) [0.000000000E+0|4.294967295E+9] ""  imc_BUSFX_2_133754

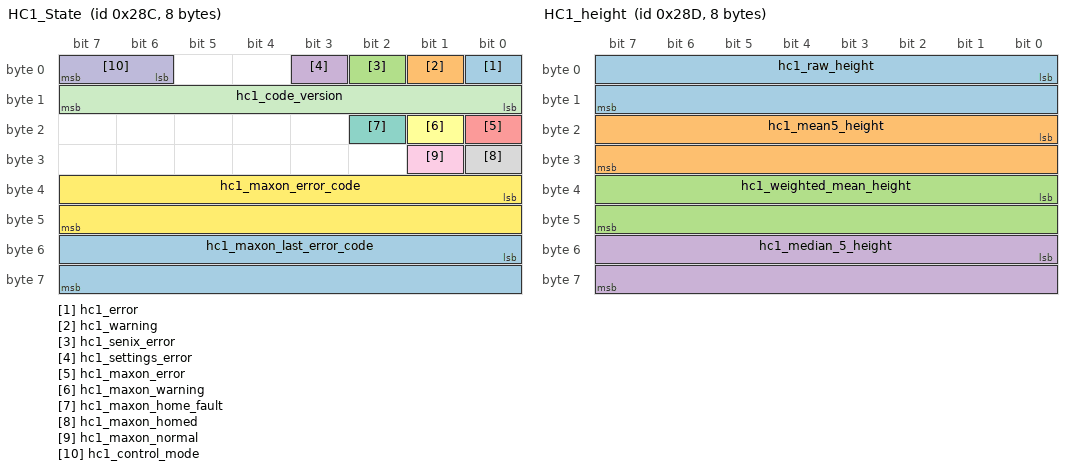
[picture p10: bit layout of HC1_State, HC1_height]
BO_ 652 HC1_State: 8 HC1
 SG_ hc1_error : 0|1@1+ (1,0) [0|1] ""  imc_BUSFX_2_133754
 SG_ hc1_warning : 1|1@1+ (1,0) [0|1] ""  imc_BUSFX_2_133754
 SG_ hc1_senix_error : 2|1@1+ (1,0) [0|1] ""  imc_BUSFX_2_133754
 SG_ hc1_settings_error : 3|1@1+ (1,0) [0|1] ""  imc_BUSFX_2_133754
 SG_ hc1_maxon_error : 16|1@1+ (1,0) [0|1] ""  imc_BUSFX_2_133754
 SG_ hc1_maxon_warning : 17|1@1+ (1,0) [0|1] ""  imc_BUSFX_2_133754
 SG_ hc1_maxon_home_fault : 18|1@1+ (1,0) [0|1] ""  imc_BUSFX_2_133754
 SG_ hc1_maxon_homed : 24|1@1+ (1,0) [0|1] ""  imc_BUSFX_2_133754
 SG_ hc1_maxon_normal : 25|1@1+ (1,0) [0|1] ""  imc_BUSFX_2_133754
 SG_ hc1_control_mode : 6|2@1+ (1.000000000E+0,0.000000000E+0) [0.000000000E+0|3.000000000E+0] ""  imc_BUSFX_2_133754
 SG_ hc1_code_version : 8|8@1+ (1.000000000E+0,0.000000000E+0) [0.000000000E+0|2.550000000E+2] ""  imc_BUSFX_2_133754
 SG_ hc1_maxon_error_code : 32|16@1+ (1.000000000E+0,0.000000000E+0) [0.000000000E+0|6.553500000E+4] ""  imc_BUSFX_2_133754
 SG_ hc1_maxon_last_error_code : 48|16@1+ (1.000000000E+0,0.000000000E+0) [0.000000000E+0|6.553500000E+4] ""  imc_BUSFX_2_133754

BO_ 653 HC1_height: 8 HC1
 SG_ hc1_raw_height : 0|16@1- (1.000000000E+0,0.000000000E+0) [-3.276800000E+4|3.276700000E+4] "mm"  imc_BUSFX_2_133754
 SG_ hc1_mean5_height : 16|16@1- (1.000000000E+0,0.000000000E+0) [-3.276800000E+4|3.276700000E+4] "mm"  imc_BUSFX_2_133754
 SG_ hc1_weighted_mean_height : 32|16@1- (1.000000000E+0,0.000000000E+0) [-3.276800000E+4|3.276700000E+4] "mm"  imc_BUSFX_2_133754
 SG_ hc1_median_5_height : 48|16@1- (1.000000000E+0,0.000000000E+0) [-3.276800000E+4|3.276700000E+4] "mm"  imc_BUSFX_2_133754

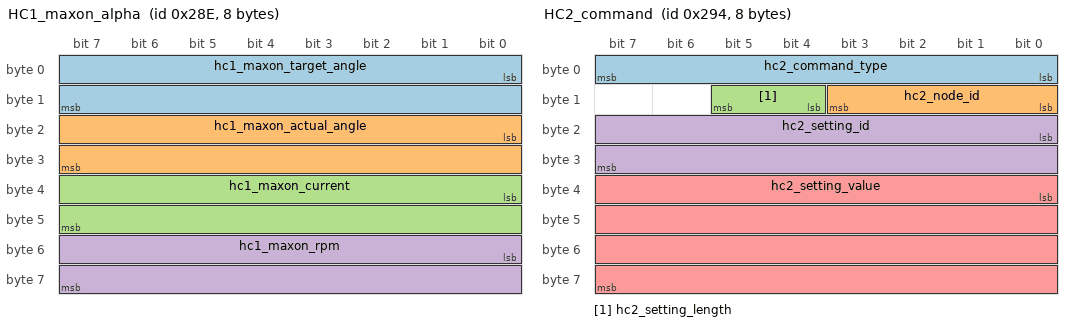
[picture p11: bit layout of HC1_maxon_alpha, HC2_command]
BO_ 654 HC1_maxon_alpha: 8 HC1
 SG_ hc1_maxon_target_angle : 0|16@1- (6.103701900E-4,0.000000000E+0) [-2.000061039E+1|2.000000002E+1] "deg"  imc_BUSFX_2_133754
 SG_ hc1_maxon_actual_angle : 16|16@1- (6.103701900E-4,0.000000000E+0) [-2.000061039E+1|2.000000002E+1] "deg"  imc_BUSFX_2_133754
 SG_ hc1_maxon_current : 32|16@1- (1.000000000E+0,0.000000000E+0) [-3.276800000E+4|3.276700000E+4] "mA"  imc_BUSFX_2_133754
 SG_ hc1_maxon_rpm : 48|16@1- (1.000000000E+0,0.000000000E+0) [-3.276800000E+4|3.276700000E+4] "rpm"  imc_BUSFX_2_133754

BO_ 655 HC1_maxon_position: 8 HC1
 SG_ hc1_maxon_target_position : 0|32@1- (1.000000000E+0,0.000000000E+0) [-2.147483648E+9|2.147483647E+9] "inc"  imc_BUSFX_2_133754
 SG_ hc1_maxon_actual_position : 32|32@1- (1.000000000E+0,0.000000000E+0) [-2.147483648E+9|2.147483647E+9] "inc"  imc_BUSFX_2_133754

BO_ 657 HC1_P_gains: 8 HC1
 SG_ hc1_P_height : 0|32@1- (1.000000000E-5,0.000000000E+0) [-2.147483648E+4|2.147483647E+4] ""  imc_BUSFX_2_133754
 SG_ hc1_P_roll : 32|32@1- (1.000000000E-5,0.000000000E+0) [-2.147483648E+4|2.147483647E+4] ""  imc_BUSFX_2_133754

BO_ 658 HC1_I_gains: 8 HC1
 SG_ hc1_I_height : 0|32@1- (1.000000000E-5,0.000000000E+0) [-2.147483648E+4|2.147483647E+4] ""  imc_BUSFX_2_133754
 SG_ hc1_I_roll : 32|32@1- (1.000000000E-5,0.000000000E+0) [-2.147483648E+4|2.147483647E+4] ""  imc_BUSFX_2_133754

BO_ 659 HC1_D_gains: 8 HC1
 SG_ hc1_D_height : 0|32@1- (1.000000000E-5,0.000000000E+0) [-2.147483648E+4|2.147483647E+4] ""  imc_BUSFX_2_133754
 SG_ hc1_D_roll : 32|32@1- (1.000000000E-5,0.000000000E+0) [-2.147483648E+4|2.147483647E+4] ""  imc_BUSFX_2_133754

BO_ 660 HC2_command: 8 Sender__XXX
 SG_ hc2_command_type : 0|8@1+ (1.000000000E+0,0.000000000E+0) [0.000000000E+0|2.550000000E+2] ""  imc_BUSFX_2_133754
 SG_ hc2_node_id : 8|4@1+ (1.000000000E+0,0.000000000E+0) [0.000000000E+0|1.500000000E+1] ""  imc_BUSFX_2_133754
 SG_ hc2_setting_length : 12|2@1+ (1.000000000E+0,0.000000000E+0) [0.000000000E+0|3.000000000E+0] ""  imc_BUSFX_2_133754
 SG_ hc2_setting_id : 16|16@1+ (1.000000000E+0,0.000000000E+0) [0.000000000E+0|6.553500000E+4] ""  imc_BUSFX_2_133754
 SG_ hc2_setting_value : 32|32@1+ (1.000000000E+0,0.000000000E+0) [0.000000000E+0|4.294967295E+9] ""  imc_BUSFX_2_133754

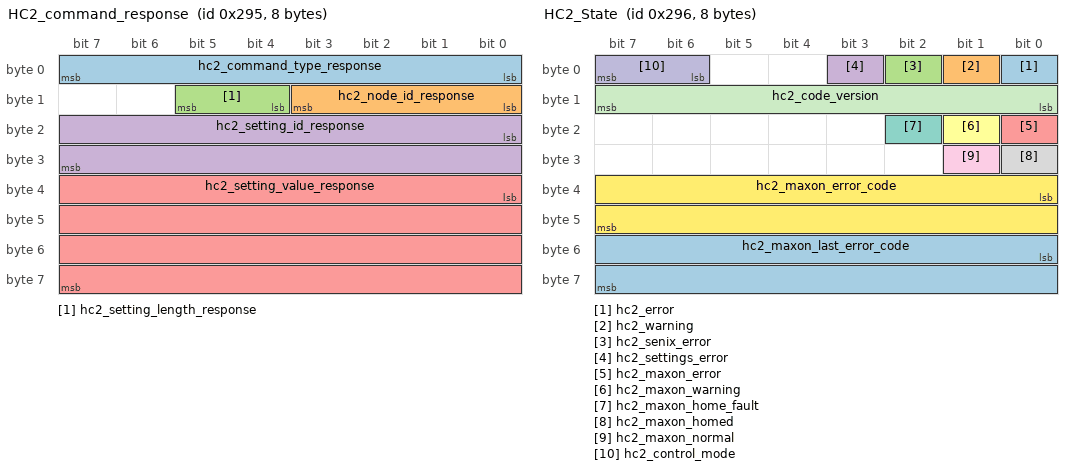
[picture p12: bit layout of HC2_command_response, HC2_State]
BO_ 661 HC2_command_response: 8 HC2
 SG_ hc2_command_type_response : 0|8@1+ (1.000000000E+0,0.000000000E+0) [0.000000000E+0|2.550000000E+2] ""  imc_BUSFX_2_133754
 SG_ hc2_node_id_response : 8|4@1+ (1.000000000E+0,0.000000000E+0) [0.000000000E+0|1.500000000E+1] ""  imc_BUSFX_2_133754
 SG_ hc2_setting_length_response : 12|2@1+ (1.000000000E+0,0.000000000E+0) [0.000000000E+0|3.000000000E+0] ""  imc_BUSFX_2_133754
 SG_ hc2_setting_id_response : 16|16@1+ (1.000000000E+0,0.000000000E+0) [0.000000000E+0|6.553500000E+4] ""  imc_BUSFX_2_133754
 SG_ hc2_setting_value_response : 32|32@1+ (1.000000000E+0,0.000000000E+0) [0.000000000E+0|4.294967295E+9] ""  imc_BUSFX_2_133754

BO_ 662 HC2_State: 8 HC2
 SG_ hc2_error : 0|1@1+ (1,0) [0|1] ""  imc_BUSFX_2_133754
 SG_ hc2_warning : 1|1@1+ (1,0) [0|1] ""  imc_BUSFX_2_133754
 SG_ hc2_senix_error : 2|1@1+ (1,0) [0|1] ""  imc_BUSFX_2_133754
 SG_ hc2_settings_error : 3|1@1+ (1,0) [0|1] ""  imc_BUSFX_2_133754
 SG_ hc2_maxon_error : 16|1@1+ (1,0) [0|1] ""  imc_BUSFX_2_133754
 SG_ hc2_maxon_warning : 17|1@1+ (1,0) [0|1] ""  imc_BUSFX_2_133754
 SG_ hc2_maxon_home_fault : 18|1@1+ (1,0) [0|1] ""  imc_BUSFX_2_133754
 SG_ hc2_maxon_homed : 24|1@1+ (1,0) [0|1] ""  imc_BUSFX_2_133754
 SG_ hc2_maxon_normal : 25|1@1+ (1,0) [0|1] ""  imc_BUSFX_2_133754
 SG_ hc2_control_mode : 6|2@1+ (1.000000000E+0,0.000000000E+0) [0.000000000E+0|3.000000000E+0] ""  imc_BUSFX_2_133754
 SG_ hc2_code_version : 8|8@1+ (1.000000000E+0,0.000000000E+0) [0.000000000E+0|2.550000000E+2] ""  imc_BUSFX_2_133754
 SG_ hc2_maxon_error_code : 32|16@1+ (1.000000000E+0,0.000000000E+0) [0.000000000E+0|6.553500000E+4] ""  imc_BUSFX_2_133754
 SG_ hc2_maxon_last_error_code : 48|16@1+ (1.000000000E+0,0.000000000E+0) [0.000000000E+0|6.553500000E+4] ""  imc_BUSFX_2_133754

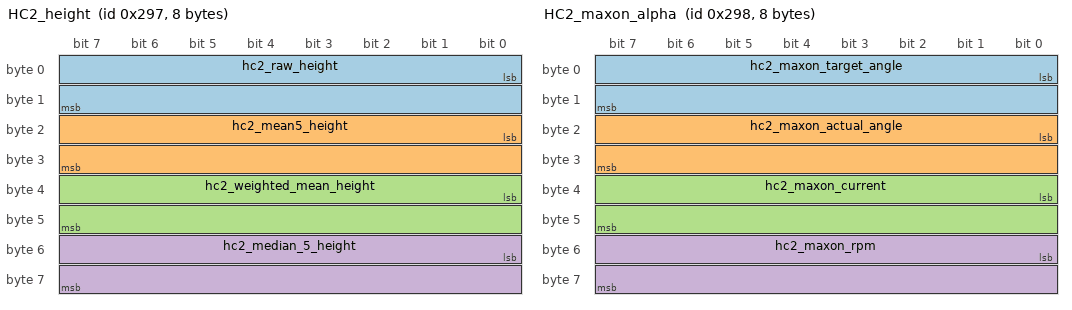
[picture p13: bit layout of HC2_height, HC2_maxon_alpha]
BO_ 663 HC2_height: 8 HC2
 SG_ hc2_raw_height : 0|16@1- (1.000000000E+0,0.000000000E+0) [-3.276800000E+4|3.276700000E+4] "mm"  imc_BUSFX_2_133754
 SG_ hc2_mean5_height : 16|16@1- (1.000000000E+0,0.000000000E+0) [-3.276800000E+4|3.276700000E+4] "mm"  imc_BUSFX_2_133754
 SG_ hc2_weighted_mean_height : 32|16@1- (1.000000000E+0,0.000000000E+0) [-3.276800000E+4|3.276700000E+4] "mm"  imc_BUSFX_2_133754
 SG_ hc2_median_5_height : 48|16@1- (1.000000000E+0,0.000000000E+0) [-3.276800000E+4|3.276700000E+4] "mm"  imc_BUSFX_2_133754

BO_ 664 HC2_maxon_alpha: 8 HC2
 SG_ hc2_maxon_target_angle : 0|16@1- (6.103701900E-4,0.000000000E+0) [-2.000061039E+1|2.000000002E+1] "deg"  imc_BUSFX_2_133754
 SG_ hc2_maxon_actual_angle : 16|16@1- (6.103701900E-4,0.000000000E+0) [-2.000061039E+1|2.000000002E+1] "deg"  imc_BUSFX_2_133754
 SG_ hc2_maxon_current : 32|16@1- (1.000000000E+0,0.000000000E+0) [-3.276800000E+4|3.276700000E+4] "mA"  imc_BUSFX_2_133754
 SG_ hc2_maxon_rpm : 48|16@1- (1.000000000E+0,0.000000000E+0) [-3.276800000E+4|3.276700000E+4] "rpm"  imc_BUSFX_2_133754

BO_ 665 HC2_maxon_position: 8 HC2
 SG_ hc2_maxon_target_position : 0|32@1- (1.000000000E+0,0.000000000E+0) [-2.147483648E+9|2.147483647E+9] "inc"  imc_BUSFX_2_133754
 SG_ hc2_maxon_actual_position : 32|32@1- (1.000000000E+0,0.000000000E+0) [-2.147483648E+9|2.147483647E+9] "inc"  imc_BUSFX_2_133754

BO_ 667 HC2_P_gains: 8 HC2
 SG_ hc2_P_height : 0|32@1- (1.000000000E-5,0.000000000E+0) [-2.147483648E+4|2.147483647E+4] ""  imc_BUSFX_2_133754
 SG_ hc2_P_roll : 32|32@1- (1.000000000E-5,0.000000000E+0) [-2.147483648E+4|2.147483647E+4] ""  imc_BUSFX_2_133754

BO_ 668 HC2_I_gains: 8 HC2
 SG_ hc2_I_height : 0|32@1- (1.000000000E-5,0.000000000E+0) [-2.147483648E+4|2.147483647E+4] ""  imc_BUSFX_2_133754
 SG_ hc2_I_roll : 32|32@1- (1.000000000E-5,0.000000000E+0) [-2.147483648E+4|2.147483647E+4] ""  imc_BUSFX_2_133754

BO_ 669 HC2_D_gains: 8 HC2
 SG_ hc2_D_height : 0|32@1- (1.000000000E-5,0.000000000E+0) [-2.147483648E+4|2.147483647E+4] ""  imc_BUSFX_2_133754
 SG_ hc2_D_roll : 32|32@1- (1.000000000E-5,0.000000000E+0) [-2.147483648E+4|2.147483647E+4] ""  imc_BUSFX_2_133754

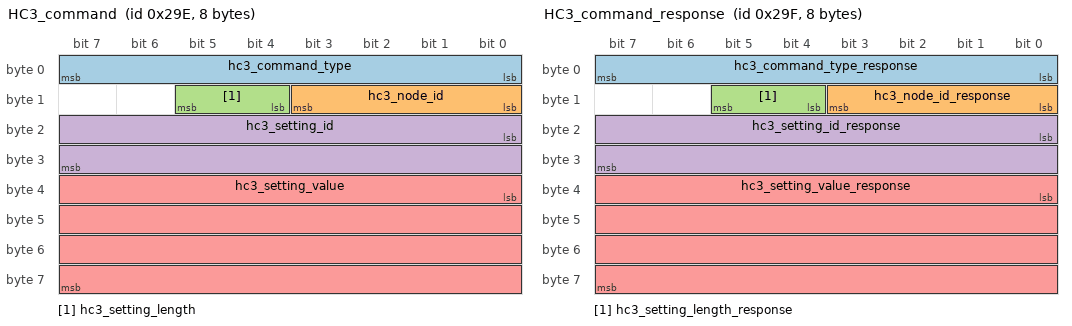
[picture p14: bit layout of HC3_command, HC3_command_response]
BO_ 670 HC3_command: 8 Sender__XXX
 SG_ hc3_command_type : 0|8@1+ (1.000000000E+0,0.000000000E+0) [0.000000000E+0|2.550000000E+2] ""  imc_BUSFX_2_133754
 SG_ hc3_node_id : 8|4@1+ (1.000000000E+0,0.000000000E+0) [0.000000000E+0|1.500000000E+1] ""  imc_BUSFX_2_133754
 SG_ hc3_setting_length : 12|2@1+ (1.000000000E+0,0.000000000E+0) [0.000000000E+0|3.000000000E+0] ""  imc_BUSFX_2_133754
 SG_ hc3_setting_id : 16|16@1+ (1.000000000E+0,0.000000000E+0) [0.000000000E+0|6.553500000E+4] ""  imc_BUSFX_2_133754
 SG_ hc3_setting_value : 32|32@1+ (1.000000000E+0,0.000000000E+0) [0.000000000E+0|4.294967295E+9] ""  imc_BUSFX_2_133754

BO_ 671 HC3_command_response: 8 HC3
 SG_ hc3_command_type_response : 0|8@1+ (1.000000000E+0,0.000000000E+0) [0.000000000E+0|2.550000000E+2] ""  imc_BUSFX_2_133754
 SG_ hc3_node_id_response : 8|4@1+ (1.000000000E+0,0.000000000E+0) [0.000000000E+0|1.500000000E+1] ""  imc_BUSFX_2_133754
 SG_ hc3_setting_length_response : 12|2@1+ (1.000000000E+0,0.000000000E+0) [0.000000000E+0|3.000000000E+0] ""  imc_BUSFX_2_133754
 SG_ hc3_setting_id_response : 16|16@1+ (1.000000000E+0,0.000000000E+0) [0.000000000E+0|6.553500000E+4] ""  imc_BUSFX_2_133754
 SG_ hc3_setting_value_response : 32|32@1+ (1.000000000E+0,0.000000000E+0) [0.000000000E+0|4.294967295E+9] ""  imc_BUSFX_2_133754

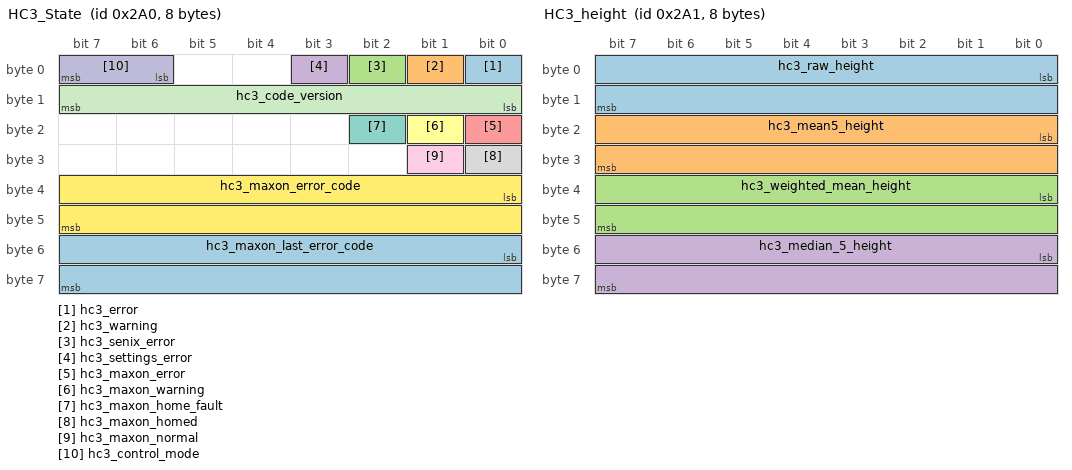
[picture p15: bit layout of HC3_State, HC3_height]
BO_ 672 HC3_State: 8 HC3
 SG_ hc3_error : 0|1@1+ (1,0) [0|1] ""  imc_BUSFX_2_133754
 SG_ hc3_warning : 1|1@1+ (1,0) [0|1] ""  imc_BUSFX_2_133754
 SG_ hc3_senix_error : 2|1@1+ (1,0) [0|1] ""  imc_BUSFX_2_133754
 SG_ hc3_settings_error : 3|1@1+ (1,0) [0|1] ""  imc_BUSFX_2_133754
 SG_ hc3_maxon_error : 16|1@1+ (1,0) [0|1] ""  imc_BUSFX_2_133754
 SG_ hc3_maxon_warning : 17|1@1+ (1,0) [0|1] ""  imc_BUSFX_2_133754
 SG_ hc3_maxon_home_fault : 18|1@1+ (1,0) [0|1] ""  imc_BUSFX_2_133754
 SG_ hc3_maxon_homed : 24|1@1+ (1,0) [0|1] ""  imc_BUSFX_2_133754
 SG_ hc3_maxon_normal : 25|1@1+ (1,0) [0|1] ""  imc_BUSFX_2_133754
 SG_ hc3_control_mode : 6|2@1+ (1.000000000E+0,0.000000000E+0) [0.000000000E+0|3.000000000E+0] ""  imc_BUSFX_2_133754
 SG_ hc3_code_version : 8|8@1+ (1.000000000E+0,0.000000000E+0) [0.000000000E+0|2.550000000E+2] ""  imc_BUSFX_2_133754
 SG_ hc3_maxon_error_code : 32|16@1+ (1.000000000E+0,0.000000000E+0) [0.000000000E+0|6.553500000E+4] ""  imc_BUSFX_2_133754
 SG_ hc3_maxon_last_error_code : 48|16@1+ (1.000000000E+0,0.000000000E+0) [0.000000000E+0|6.553500000E+4] ""  imc_BUSFX_2_133754

BO_ 673 HC3_height: 8 HC3
 SG_ hc3_raw_height : 0|16@1- (1.000000000E+0,0.000000000E+0) [-3.276800000E+4|3.276700000E+4] "mm"  imc_BUSFX_2_133754
 SG_ hc3_mean5_height : 16|16@1- (1.000000000E+0,0.000000000E+0) [-3.276800000E+4|3.276700000E+4] "mm"  imc_BUSFX_2_133754
 SG_ hc3_weighted_mean_height : 32|16@1- (1.000000000E+0,0.000000000E+0) [-3.276800000E+4|3.276700000E+4] "mm"  imc_BUSFX_2_133754
 SG_ hc3_median_5_height : 48|16@1- (1.000000000E+0,0.000000000E+0) [-3.276800000E+4|3.276700000E+4] "mm"  imc_BUSFX_2_133754

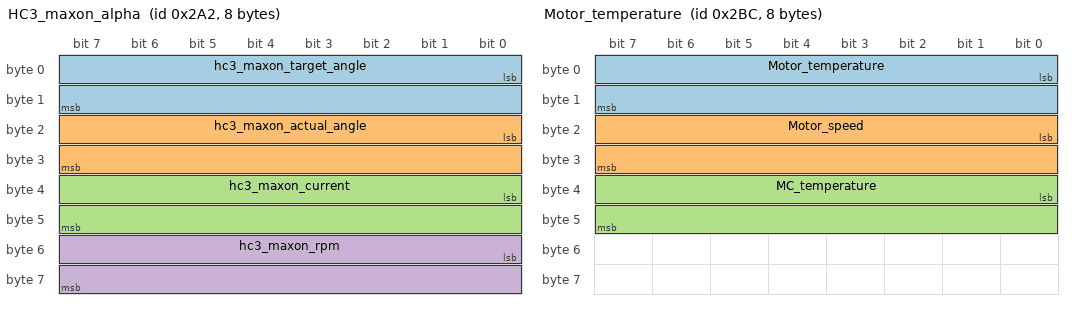
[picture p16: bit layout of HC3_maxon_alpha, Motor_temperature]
BO_ 674 HC3_maxon_alpha: 8 HC3
 SG_ hc3_maxon_target_angle : 0|16@1- (6.103701900E-4,0.000000000E+0) [-2.000061039E+1|2.000000002E+1] "deg"  imc_BUSFX_2_133754
 SG_ hc3_maxon_actual_angle : 16|16@1- (6.103701900E-4,0.000000000E+0) [-2.000061039E+1|2.000000002E+1] "deg"  imc_BUSFX_2_133754
 SG_ hc3_maxon_current : 32|16@1- (1.000000000E+0,0.000000000E+0) [-3.276800000E+4|3.276700000E+4] "mA"  imc_BUSFX_2_133754
 SG_ hc3_maxon_rpm : 48|16@1- (1.000000000E+0,0.000000000E+0) [-3.276800000E+4|3.276700000E+4] "rpm"  imc_BUSFX_2_133754

BO_ 675 HC3_maxon_position: 8 HC3
 SG_ hc3_maxon_target_position : 0|32@1- (1.000000000E+0,0.000000000E+0) [-2.147483648E+9|2.147483647E+9] "inc"  imc_BUSFX_2_133754
 SG_ hc3_maxon_actual_position : 32|32@1- (1.000000000E+0,0.000000000E+0) [-2.147483648E+9|2.147483647E+9] "inc"  imc_BUSFX_2_133754

BO_ 677 HC3_P_gains: 8 HC3
 SG_ hc3_P_height : 0|32@1- (1.000000000E-5,0.000000000E+0) [-2.147483648E+4|2.147483647E+4] ""  imc_BUSFX_2_133754
 SG_ hc3_P_roll : 32|32@1- (1.000000000E-5,0.000000000E+0) [-2.147483648E+4|2.147483647E+4] ""  imc_BUSFX_2_133754

BO_ 678 HC3_I_gains: 8 HC3
 SG_ hc3_I_height : 0|32@1- (1.000000000E-5,0.000000000E+0) [-2.147483648E+4|2.147483647E+4] ""  imc_BUSFX_2_133754
 SG_ hc3_I_roll : 32|32@1- (1.000000000E-5,0.000000000E+0) [-2.147483648E+4|2.147483647E+4] ""  imc_BUSFX_2_133754

BO_ 679 HC3_D_gains: 8 HC3
 SG_ hc3_D_height : 0|32@1- (1.000000000E-5,0.000000000E+0) [-2.147483648E+4|2.147483647E+4] ""  imc_BUSFX_2_133754
 SG_ hc3_D_roll : 32|32@1- (1.000000000E-5,0.000000000E+0) [-2.147483648E+4|2.147483647E+4] ""  imc_BUSFX_2_133754

BO_ 465 FuellCell_CDR: 2 Sender__XXX
 SG_ FC_CurrentDrawRequest : 0|16@1+ (1.000000000E-1,0.000000000E+0) [0.000000000E+0|6.553500000E+3] "A"  imc_BUSFX_2_133754

BO_ 700 Motor_temperature: 8 Sender__XXX
 SG_ Motor_temperature : 0|16@1- (1.821428571E-2,-1.712142857E+2) [-7.680599999E+2|4.256132141E+2] "C"  imc_BUSFX_2_133754
 SG_ Motor_speed : 16|16@1- (2.500000000E-4,0.000000000E+0) [-8.192000000E+0|8.191750000E+0] "rpm"  imc_BUSFX_2_133754
 SG_ MC_temperature : 32|16@1- (1.821428571E-2,-1.712142857E+2) [-7.680599999E+2|4.256132141E+2] "C"  imc_BUSFX_2_133754

BO_ 449 FuelCell_CMD: 1 Sender__XXX
 SG_ FC_StateCommand : 0|8@1- (1.000000000E+0,0.000000000E+0) [-1.280000000E+2|1.270000000E+2] "V"  imc_BUSFX_2_133754

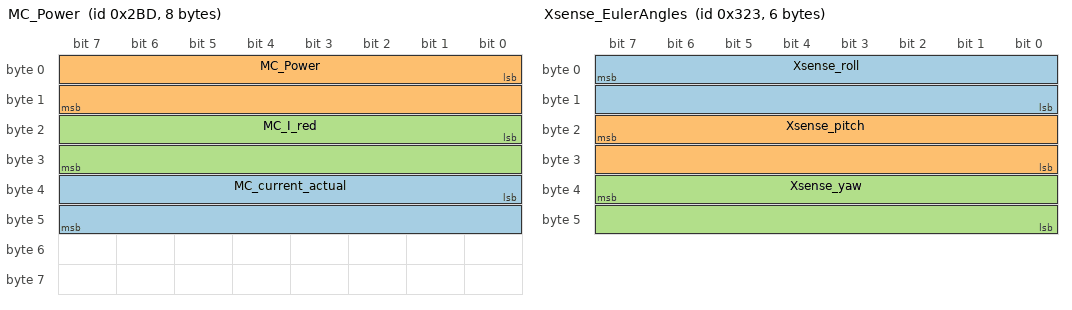
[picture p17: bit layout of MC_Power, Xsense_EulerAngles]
BO_ 701 MC_Power: 8 Sender__XXX
 SG_ MC_current_actual : 32|16@1- (1.000000000E+0,0.000000000E+0) [-3.276800000E+4|3.276700000E+4] "A"  imc_BUSFX_2_133754
 SG_ MC_Power : 0|16@1- (1.000000000E+0,0.000000000E+0) [-3.276800000E+4|3.276700000E+4] "W"  imc_BUSFX_2_133754
 SG_ MC_I_red : 16|16@1- (1.000000000E+0,0.000000000E+0) [-3.276800000E+4|3.276700000E+4] "A"  imc_BUSFX_2_133754

BO_ 809 Xsens_longlat: 4 Sender__XXX
 SG_ Xsens_longitude : 23|16@0- (7.812499990E-3,0.000000000E+0) [-2.559999997E+2|2.559921872E+2] "degree"  imc_BUSFX_2_133754
 SG_ Xsens_latitude : 7|16@0- (3.906249990E-3,0.000000000E+0) [-1.279999997E+2|1.279960934E+2] "degree"  imc_BUSFX_2_133754

BO_ 705 FC_FaultsAlarms: 8 Sender__XXX
 SG_ FC_Faults_UnderV : 0|1@1+ (1,0) [0|1] ""  imc_BUSFX_2_133754
 SG_ FC_Faults_OverTemo : 1|1@1+ (1,0) [0|1] ""  imc_BUSFX_2_133754
 SG_ FC_Faults_HearthBeat : 4|1@1+ (1,0) [0|1] ""  imc_BUSFX_2_133754
 SG_ FC_Faults_Estop : 6|1@1+ (1,0) [0|1] ""  imc_BUSFX_2_133754
 SG_ FC_Faults_LeakCheck : 8|1@1+ (1,0) [0|1] ""  imc_BUSFX_2_133754
 SG_ FC_Faults_FreezeMode : 9|1@1+ (1,0) [0|1] ""  imc_BUSFX_2_133754
 SG_ FC_Faults_CoolFlow : 10|1@1+ (1,0) [0|1] ""  imc_BUSFX_2_133754
 SG_ FC_Faults_Idle : 11|1@1+ (1,0) [0|1] ""  imc_BUSFX_2_133754
 SG_ FC_Faults_AnPurge : 12|1@1+ (1,0) [0|1] ""  imc_BUSFX_2_133754
 SG_ FC_Faults_StkCurrent : 13|1@1+ (1,0) [0|1] ""  imc_BUSFX_2_133754
 SG_ FC_Faults_H2_Opressure : 14|1@1+ (1,0) [0|1] ""  imc_BUSFX_2_133754
 SG_ FC_Faults_H2_Upressure : 15|1@1+ (1,0) [0|1] ""  imc_BUSFX_2_133754
 SG_ FC_Alarms_H2_PSensRange : 32|1@1+ (1,0) [0|1] ""  imc_BUSFX_2_133754
 SG_ FC_Alarms_AirFlowRange : 33|1@1+ (1,0) [0|1] ""  imc_BUSFX_2_133754
 SG_ FC_Alarms_CsenseRange : 34|1@1+ (1,0) [0|1] ""  imc_BUSFX_2_133754
 SG_ FC_Alarms_CoolTempHigh : 35|1@1+ (1,0) [0|1] ""  imc_BUSFX_2_133754
 SG_ FC_Alarms_OverPower : 36|1@1+ (1,0) [0|1] ""  imc_BUSFX_2_133754
 SG_ FC_Alarms_NonRun : 37|1@1+ (1,0) [0|1] ""  imc_BUSFX_2_133754
 SG_ FC_Alarms_BlowFlow : 38|1@1+ (1,0) [0|1] ""  imc_BUSFX_2_133754
 SG_ FC_Alarms_AnPumpSpeed : 39|1@1+ (1,0) [0|1] ""  imc_BUSFX_2_133754
 SG_ FC_Alarms_CoolTemp : 40|1@1+ (1,0) [0|1] ""  imc_BUSFX_2_133754
 SG_ FC_Alarms_BlowVoltLow : 41|1@1+ (1,0) [0|1] ""  imc_BUSFX_2_133754
 SG_ FC_Alarms_Recovery : 42|1@1+ (1,0) [0|1] ""  imc_BUSFX_2_133754
 SG_ FC_Alarms_CoolFlow : 43|1@1+ (1,0) [0|1] ""  imc_BUSFX_2_133754
 SG_ FC_StackLowC : 44|1@1+ (1,0) [0|1] ""  imc_BUSFX_2_133754
 SG_ FC_Alarms_eFCVM_Finger : 45|1@1+ (1,0) [0|1] ""  imc_BUSFX_2_133754
 SG_ FC_Alarms_EEPROM : 46|1@1+ (1,0) [0|1] ""  imc_BUSFX_2_133754
 SG_ FC_Alarms_EMP_Pump : 47|1@1+ (1,0) [0|1] ""  imc_BUSFX_2_133754

BO_ 800 Xsense_SampleTime: 4 Xsens_Sensor
 SG_ Xsense_Timestamp : 7|32@0+ (1.000000000E+0,0.000000000E+0) [0.000000000E+0|4.294967295E+9] "us"  imc_BUSFX_2_133754

BO_ 801 Xsense_StatusWord: 4 Xsens_Sensor
 SG_ Xsense_FilterMode : 1|3@0+ (1.000000000E+0,0.000000000E+0) [0.000000000E+0|7.000000000E+0] ""  imc_BUSFX_2_133754
 SG_ HaveGnssTimePulse : 2|1@1+ (1,0) [0|1] ""  imc_BUSFX_2_133754
 SG_ ClipMagZ : 8|1@1+ (1,0) [0|1] ""  imc_BUSFX_2_133754
 SG_ Retransmitted : 10|1@1+ (1,0) [0|1] ""  imc_BUSFX_2_133754
 SG_ ClippingDetected : 11|1@1+ (1,0) [0|1] ""  imc_BUSFX_2_133754
 SG_ Interpolated : 12|1@1+ (1,0) [0|1] ""  imc_BUSFX_2_133754
 SG_ SyncIn : 13|1@1+ (1,0) [0|1] ""  imc_BUSFX_2_133754
 SG_ SyncOut : 14|1@1+ (1,0) [0|1] ""  imc_BUSFX_2_133754
 SG_ ClipAccX : 16|1@1+ (1,0) [0|1] ""  imc_BUSFX_2_133754
 SG_ ClipAccY : 17|1@1+ (1,0) [0|1] ""  imc_BUSFX_2_133754
 SG_ ClipAccZ : 18|1@1+ (1,0) [0|1] ""  imc_BUSFX_2_133754
 SG_ ClipGyrX : 19|1@1+ (1,0) [0|1] ""  imc_BUSFX_2_133754
 SG_ ClipGyrY : 20|1@1+ (1,0) [0|1] ""  imc_BUSFX_2_133754
 SG_ ClipGyrZ : 21|1@1+ (1,0) [0|1] ""  imc_BUSFX_2_133754
 SG_ ClipMagX : 22|1@1+ (1,0) [0|1] ""  imc_BUSFX_2_133754
 SG_ ClipMagY : 23|1@1+ (1,0) [0|1] ""  imc_BUSFX_2_133754
 SG_ SelfTestOk : 24|1@1+ (1,0) [0|1] ""  imc_BUSFX_2_133754
 SG_ Xsense_RtkStatus : 4|2@0+ (1.000000000E+0,0.000000000E+0) [0.000000000E+0|3.000000000E+0] ""  imc_BUSFX_2_133754
 SG_ OrientationValid : 25|1@1+ (1,0) [0|1] ""  imc_BUSFX_2_133754
 SG_ GpsValid : 26|1@1+ (1,0) [0|1] ""  imc_BUSFX_2_133754
 SG_ RepresentativeMotion : 29|1@1+ (1,0) [0|1] ""  imc_BUSFX_2_133754
 SG_ ExternalClockSynced : 30|1@1+ (1,0) [0|1] ""  imc_BUSFX_2_133754
 SG_ Xsense_NoRotation : 28|2@0+ (1.000000000E+0,0.000000000E+0) [0.000000000E+0|3.000000000E+0] ""  imc_BUSFX_2_133754

BO_ 803 Xsense_EulerAngles: 6 Xsens_Sensor
 SG_ Xsense_roll : 7|16@0- (7.812500000E-3,0.000000000E+0) [-2.560000000E+2|2.559921875E+2] "deg"  imc_BUSFX_2_133754
 SG_ Xsense_pitch : 23|16@0- (7.812500000E-3,0.000000000E+0) [-2.560000000E+2|2.559921875E+2] "deg"  imc_BUSFX_2_133754
 SG_ Xsense_yaw : 39|16@0- (7.812500000E-3,0.000000000E+0) [-2.560000000E+2|2.559921875E+2] "deg"  imc_BUSFX_2_133754

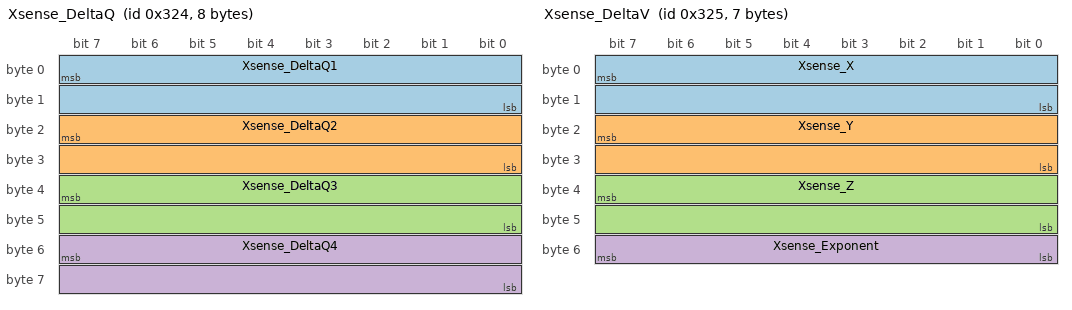
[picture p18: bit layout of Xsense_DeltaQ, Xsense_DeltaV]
BO_ 804 Xsense_DeltaQ: 8 Xsens_Sensor
 SG_ Xsense_DeltaQ1 : 7|16@0- (3.051850948E-5,0.000000000E+0) [-1.000030519E+0|1.000000000E+0] "m/s2"  imc_BUSFX_2_133754
 SG_ Xsense_DeltaQ2 : 23|16@0- (3.051850948E-5,0.000000000E+0) [-1.000030519E+0|1.000000000E+0] "m/s2"  imc_BUSFX_2_133754
 SG_ Xsense_DeltaQ3 : 39|16@0- (3.051850948E-5,0.000000000E+0) [-1.000030519E+0|1.000000000E+0] "m/s2"  imc_BUSFX_2_133754
 SG_ Xsense_DeltaQ4 : 55|16@0- (3.051850948E-5,0.000000000E+0) [-1.000030519E+0|1.000000000E+0] "m/s2"  imc_BUSFX_2_133754

BO_ 805 Xsense_DeltaV: 7 Xsens_Sensor
 SG_ Xsense_X : 7|16@0- (7.629394531E-6,0.000000000E+0) [-2.500000000E-1|2.499923706E-1] "m/s"  imc_BUSFX_2_133754
 SG_ Xsense_Y : 23|16@0- (7.629394531E-6,0.000000000E+0) [-2.500000000E-1|2.499923706E-1] "m/s"  imc_BUSFX_2_133754
 SG_ Xsense_Z : 39|16@0- (7.629394531E-6,0.000000000E+0) [-2.500000000E-1|2.499923706E-1] "m/s"  imc_BUSFX_2_133754
 SG_ Xsense_Exponent : 55|8@0+ (1.000000000E+0,0.000000000E+0) [0.000000000E+0|2.550000000E+2] ""  imc_BUSFX_2_133754

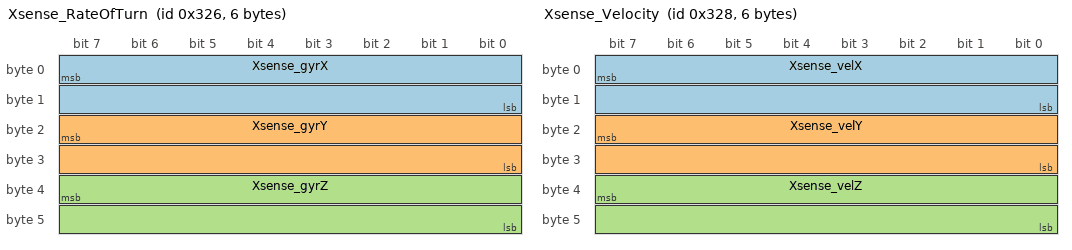
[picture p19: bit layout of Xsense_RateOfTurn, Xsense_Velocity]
BO_ 806 Xsense_RateOfTurn: 6 Xsens_Sensor
 SG_ Xsense_gyrX : 7|16@0- (1.953125000E-3,0.000000000E+0) [-6.400000000E+1|6.399804688E+1] "rad/s"  imc_BUSFX_2_133754
 SG_ Xsense_gyrY : 23|16@0- (1.953125000E-3,0.000000000E+0) [-6.400000000E+1|6.399804688E+1] "rad/s"  imc_BUSFX_2_133754
 SG_ Xsense_gyrZ : 39|16@0- (1.953125000E-3,0.000000000E+0) [-6.400000000E+1|6.399804688E+1] "rad/s"  imc_BUSFX_2_133754

BO_ 807 Xsense_LongLat: 8 Xsens_Sensor
 SG_ Xsense_latitude : 7|32@0- (5.960464477E-8,0.000000000E+0) [-1.280000000E+2|1.279999999E+2] "deg"  imc_BUSFX_2_133754
 SG_ Xsense_longitude : 39|32@0- (1.192092895E-7,0.000000000E+0) [-2.559999999E+2|2.559999998E+2] "deg"  imc_BUSFX_2_133754

BO_ 808 Xsense_Velocity: 6 Xsens_Sensor
 SG_ Xsense_velX : 7|16@0- (1.562500000E-2,0.000000000E+0) [-5.120000000E+2|5.119843750E+2] "m/s"  imc_BUSFX_2_133754
 SG_ Xsense_velY : 23|16@0- (1.562500000E-2,0.000000000E+0) [-5.120000000E+2|5.119843750E+2] "m/s"  imc_BUSFX_2_133754
 SG_ Xsense_velZ : 39|16@0- (1.562500000E-2,0.000000000E+0) [-5.120000000E+2|5.119843750E+2] "m/s"  imc_BUSFX_2_133754

BO_ 833 FC_Temp: 8 Sender__XXX
 SG_ FC_Temp_Coolant : 0|16@1- (1.000000000E-1,0.000000000E+0) [-3.276800000E+3|3.276700000E+3] "C"  imc_BUSFX_2_133754
 SG_ FC_Temp_CoolantSetPoint : 16|16@1- (1.000000000E-1,0.000000000E+0) [-3.276800000E+3|3.276700000E+3] "C"  imc_BUSFX_2_133754

BO_ 1313 Shunt_Current: 6 Sender__XXX
 SG_ Shunt_Current_msg : 16|32@1- (-1.000000000E-3,0.000000000E+0) [2.147483648E+6|-2.147483647E+6] "A"  imc_BUSFX_2_133754

BO_ 1400 BMS_Overall: 8 Sender__XXX
 SG_ BMS_Overall_NumbOfCellsMSB : 16|8@1+ (2.560000000E+2,0.000000000E+0) [0.000000000E+0|6.528000000E+4] ""  imc_BUSFX_2_133754
 SG_ BMS_Overall_NumbOfCellsLSB : 56|8@1+ (1.000000000E+0,0.000000000E+0) [0.000000000E+0|2.550000000E+2] ""  imc_BUSFX_2_133754

BO_ 1401 BMS_Parameters: 8 Sender__XXX
 SG_ BMS_Voltage_MinCellVoltage : 0|8@1+ (1.000000000E-2,2.000000000E+0) [2.000000000E+0|4.550000000E+0] "V"  imc_BUSFX_2_133754
 SG_ BMS_Voltage_MaxCellVoltage : 8|8@1+ (1.000000000E-2,2.000000000E+0) [2.000000000E+0|4.550000000E+0] "V"  imc_BUSFX_2_133754
 SG_ BMS_Voltage_AvrCellVoltage : 16|8@1+ (1.000000000E-2,2.000000000E+0) [2.000000000E+0|4.550000000E+0] "V"  imc_BUSFX_2_133754
 SG_ BMS_Voltage_TotalVbyte2 : 24|8@1+ (2.560000000E+0,0.000000000E+0) [0.000000000E+0|6.528000000E+2] "V"  imc_BUSFX_2_133754
 SG_ BMS_Voltage_TotalVbyte3 : 32|8@1+ (1.000000000E-2,0.000000000E+0) [0.000000000E+0|2.550000000E+0] "V"  imc_BUSFX_2_133754
 SG_ BMS_Voltage_TotalVbyte0 : 40|8@1+ (1.677721600E+5,0.000000000E+0) [0.000000000E+0|4.278190080E+7] "V"  imc_BUSFX_2_133754
 SG_ BMS_Voltage_TotalVbyte1 : 40|8@1+ (6.553600000E+2,0.000000000E+0) [0.000000000E+0|1.671168000E+5] "V"  imc_BUSFX_2_133754

BO_ 1403 BMS_CellBallancing: 8 Sender__XXX
 SG_ BMS_CellBallancing_Avg : 0|8@1+ (3.921568627E-1,0.000000000E+0) [0.000000000E+0|9.999999999E+1] "%"  imc_BUSFX_2_133754
 SG_ BMS_CellBallancing_Min : 0|8@1+ (3.921568627E-1,0.000000000E+0) [0.000000000E+0|9.999999999E+1] "%"  imc_BUSFX_2_133754
 SG_ BMS_CellBallancing_Max : 8|8@1+ (3.921568627E-1,0.000000000E+0) [0.000000000E+0|9.999999999E+1] "%"  imc_BUSFX_2_133754

BO_ 1405 BMS_SOC: 8 Sender__XXX
 SG_ BMS_SOC_Current : 7|16@0- (1.000000000E-1,0.000000000E+0) [-3.276800000E+3|3.276700000E+3] "A"  imc_BUSFX_2_133754
 SG_ BMS_SOC_EstimatedCharge : 23|16@0- (1.000000000E-1,0.000000000E+0) [-3.276800000E+3|3.276700000E+3] "Ah"  imc_BUSFX_2_133754
 SG_ BMS_SOC_EstimatedStateOfCharge : 48|8@1- (1.000000000E+0,0.000000000E+0) [-1.280000000E+2|1.270000000E+2] "%"  imc_BUSFX_2_133754

BO_ 1408 BMS_CellTemp: 8 Sender__XXX
 SG_ BMS_CellTemp_Min : 0|8@1+ (1.000000000E+0,-1.000000000E+2) [-1.000000000E+2|1.550000000E+2] "C"  imc_BUSFX_2_133754
 SG_ BMS_CellTemp_Max : 8|8@1+ (1.000000000E+0,-1.000000000E+2) [-1.000000000E+2|1.550000000E+2] "C"  imc_BUSFX_2_133754
 SG_ BMS_CellTemp_Avg : 16|8@1+ (1.000000000E+0,-1.000000000E+2) [-1.000000000E+2|1.550000000E+2] "C"  imc_BUSFX_2_133754

BO_ 1600 HydrogenSensor1: 8 Sender__XXX
 SG_ HydrogenSensor1_HydrogenLevel : 0|8@1+ (2.000000000E-2,-4.000000000E-1) [-4.000000000E-1|4.700000000E+0] "%"  imc_BUSFX_2_133754

BO_ 1608 HydrogenSensor2: 8 Sender__XXX
 SG_ HydrogenSensor2_HydrogenLevel : 0|8@1+ (2.000000000E-2,-4.000000000E-1) [-4.000000000E-1|4.700000000E+0] "%"  imc_BUSFX_2_133754

BO_ 1 DCDC_current: 3 Sender__XXX
 SG_ DCDC_current_command : 7|16@0+ (3.125000000E-2,-1.024000000E+3) [-1.024000000E+3|1.023968750E+3] "A"  imc_BUSFX_2_133754

CM_ "CAN-database created with: imc DEVICES 2.13 Rev. 11";
CM_ BO_ 16 "Msg 1 from BDC546 to SG (main message) 10ms";
CM_ SG_ 16 BDC_ILS_max_Lim "Max low side current limiter active. Values: 1 On 0 Off ";
CM_ SG_ 16 BDC_ILS_min_Lim "Min low side current limiter active. Values: 1 On 0 Off ";
CM_ SG_ 16 BDC_ULS_max_Lim "Max low side voltage limiter active. Values: 1 On 0 Off ";
CM_ SG_ 16 BDC_ULS_min_Lim "Min low side voltage limiter active. Values: 1 On 0 Off ";
CM_ SG_ 16 BDC_IHS_max_Lim "Max high side current limiter active. Values: 1 On 0 Off ";
CM_ SG_ 16 BDC_IHS_min_Lim "Min high side current limiter active. Values: 1 On 0 Off ";
CM_ SG_ 16 BDC_UHS_max_Lim "Max high side voltage limiter active. Values: 1 On 0 Off ";
CM_ SG_ 16 BDC_UHS_min_Lim "Min high side voltage limiter active. Values: 1 On 0 Off ";
CM_ SG_ 16 BDC_Ready "BDC546 Ready. Values: 1 On 0 Off ";
CM_ SG_ 16 BDC_Running "BDC546 Running. Values: 1 On 0 Off ";
CM_ SG_ 16 BDC_Warning "BDC546 Warning. Values: 1 On 0 Off ";
CM_ SG_ 16 BDC_Error "BDC546 Error. Values: 1 On 0 Off ";
CM_ SG_ 16 DCDC_ILS_act "Low side current value";
CM_ SG_ 16 DCDC_IHS_act "High side current value";
CM_ SG_ 16 DCDC_ULS_act "Low side voltage value";
CM_ SG_ 16 DCDC_UHS_act "High side voltage value";
CM_ BO_ 17 "Msg 2 from BDC546 to SG (Values and Config) 200ms";
CM_ SG_ 17 DCDC_ILS_available "Max low side current due to derating";
CM_ SG_ 17 DCDC_T_Index "Measured temperature count (index)";
CM_ SG_ 17 DCDC_T "Measured temperature at this index";
CM_ SG_ 17 DCDC_T_max "Max measured temperatur BDC546";
CM_ SG_ 17 DCDC_ULS_act_red "Redundant low side voltage value";
CM_ SG_ 17 DCDC_UHS_act_red "Redundant high side voltage value";
CM_ BO_ 18 "Msg 3 from BDC546 to SG (Errors and Warnings) 200ms";
CM_ SG_ 18 BDC_Err_RedNegLS "BDC Error negative difference redundant voltage measurement low-side";
CM_ SG_ 18 BDC_Err_RedPosLS "BDC Error positive difference redundant voltage measurement low-side";
CM_ SG_ 18 BDC_Err_PyroMC "BDC Error Pyrofuse ignition";
CM_ SG_ 18 BDC_Err_TempSens "BDC Error Temperatur sensors (at least two sensors defective)";
CM_ SG_ 18 BDC_Err_Interlock "BDC Error Interlock detection";
CM_ SG_ 18 BDC_Err_ISensLS "BDC Error current sensor low-side at initialisation";
CM_ SG_ 18 BDC_Err_ISensHS "BDC Error current sensor high-side at initialisation";
CM_ SG_ 18 BDC_Err_BDCMode "BDC Error Not the same mode between CAN and PARAM values";
CM_ SG_ 18 BDC_Err_IHS2ILS "BDC Error plausibility IHS to ILS";
CM_ SG_ 18 BDC_Err_RedNegHS "BDC Error negative difference redundant voltage measurement high-side";
CM_ SG_ 18 BDC_Err_RedPosHS "BDC Error postive difference redundant voltage measurement high-side";
CM_ SG_ 18 BDC_Err_Timeout_Recv3 "BDC Error message Recv3 timeout";
CM_ SG_ 18 BDC_Err_Timeout_Recv2 "BDC Error message Recv2 timeout";
CM_ SG_ 18 BDC_Err_Timeout_Recv1 "BDC Error message Recv1 timeout";
CM_ SG_ 18 BDC_Err_CANValue "BDC Error received CAN signal with wrong value";
CM_ SG_ 18 BDC_Err_IntSupply "BDC Error Internal supply (15V) not running if HV is connected";
CM_ SG_ 18 BDC_Err_FPGA "BDC Error from FPGA";
CM_ SG_ 18 BDC_Err_NVSRam "BDC Error NVSRam not available or wrong version";
CM_ SG_ 18 BDC_Err_Flash "BDC Error flash CRC wrong";
CM_ SG_ 18 BDC_Err_EEProm "BDC Error main parameter set failure";
CM_ SG_ 18 BDC_Err_HW_FPGA_Ver "BDC Error HW or FPGA version not korrekt";
CM_ SG_ 18 BDC_Err_CANTx "BDC Error too many CAN Tx failures";
CM_ SG_ 18 BDC_Err_CANRx "BDC Error too many CAN Rx failures";
CM_ SG_ 18 BDC_Err_CANOff "BDC Error CAN off at uC";
CM_ SG_ 18 BDC_Err_OvltSky "BDC Error internal supply (15V) overvoltage";
CM_ SG_ 18 BDC_Err_OvltLS "BDC Error low-side overvoltage";
CM_ SG_ 18 BDC_Err_OvltHS "BDC Error high-side overvoltage";
CM_ SG_ 18 BDC_War_TempIndD "BDC Warning temperatur sensor inductor D defective";
CM_ SG_ 18 BDC_War_TempIndC "BDC Warning temperatur sensor inductor C defective";
CM_ SG_ 18 BDC_War_TempIndB "BDC Warning temperatur sensor inductor B defective";
CM_ SG_ 18 BDC_War_TempIndA "BDC Warning temperatur sensor inductor A defective";
CM_ SG_ 18 BDC_War_Reset "BDC Warning System was reset";
CM_ SG_ 18 BDC_War_IMax "BDC Warning Derating active";
CM_ SG_ 18 BDC_War_Watchdog "BDC Warning Watchdog had caused the last reset";
CM_ SG_ 18 BDC_War_TempL2x "BDC Warning temperatur sensor module L2x defective";
CM_ SG_ 18 BDC_War_TempL1y "BDC Warning temperatur sensor module L1y defective";
CM_ SG_ 18 BDC_War_TempL1x "BDC Warning temperatur sensor module L1x defective";
CM_ SG_ 18 BDC_Err_FPGA_NVM "BDC Error FPGA NVM CRC check";
CM_ SG_ 18 BDC_War_TempL4y "BDC Warning temperatur sensor module L4y defective";
CM_ SG_ 18 BDC_War_TempL4x "BDC Warning temperatur sensor module L4x defective";
CM_ SG_ 18 BDC_War_TempL3y "BDC Warning temperatur sensor module L3y defective";
CM_ SG_ 18 BDC_War_TempL3x "BDC Warning temperatur sensor module L3x defective";
CM_ SG_ 18 BDC_War_TempL2y "BDC Warning temperatur sensor module L2y defective";
CM_ SG_ 18 BDC_War_HSOvervoltage "BDC Warning FPGA has switched off with HS Overvoltage";
CM_ SG_ 18 BDC_War_NoIntSupply "BDC Warning no internal supply (15V)";
CM_ SG_ 18 BDC_War_NoHV_UHS "BDC Warning no HV at high-side";
CM_ SG_ 18 BDC_War_WrongFPGA "BDC Warning wrong FPGA version";
CM_ SG_ 18 BDC_War_WrongHW "BDC Warning wrong HW versions";
CM_ SG_ 18 BDC_War_PyroVCneg "BDC Warning Pyrofuse negative resistance wrong";
CM_ SG_ 18 BDC_War_PyroVCpos "BDC Warning Pyrofuse positive resistance wrong";
CM_ SG_ 18 BDC_War_Discharge "BDC Warning Voltage too high after discharge";
CM_ SG_ 18 BDC_War_CAN_Timeout "BDC Warning CAN Timeout was detected";
CM_ SG_ 18 BDC_War_LSOvervoltage "BDC Warning FPGA has switched off with LS Overvoltage";
CM_ BO_ 19 "Msg 3 from BDC546 to SG (Errors and Warnings) 200ms";
CM_ SG_ 19 DCDC_SG_IL_max "Minimum inductor current measured";
CM_ SG_ 577 FC_State_Callowed "Current Draw Allowed";
CM_ SG_ 577 FC_State_Cstack "Fuel Cell Current";
CM_ SG_ 577 FC_State_Vstack "Fuel Cell";
CM_ BO_ 640 "pass command to hc node";
CM_ SG_ 640 hc0_command_type "get or set a setting. 0x10 is get, 0x20 is set.";
CM_ SG_ 640 hc0_node_id "node id to change it in.";
CM_ SG_ 640 hc0_setting_length "length ot the message command stuff";
CM_ SG_ 640 hc0_setting_id "settings id to change";
CM_ SG_ 640 hc0_setting_value "new value of the setting if it is set";
CM_ BO_ 641 "pass command to hc node";
CM_ SG_ 641 hc0_command_type_response "get or set a setting. 0x10 is get, 0x20 is set.";
CM_ SG_ 641 hc0_node_id_response "node id to change it in.";
CM_ SG_ 641 hc0_setting_length_response "length ot the message command stuff";
CM_ SG_ 641 hc0_setting_id_response "settings id to change that was specified";
CM_ SG_ 641 hc0_setting_value_response "current value of the setting";
CM_ BO_ 642 "the state of the HC node with errors and problems ";
CM_ SG_ 642 hc0_error "There was an error with HC";
CM_ SG_ 642 hc0_warning "non fatal problem with ";
CM_ SG_ 642 hc0_senix_error "error with the senix";
CM_ SG_ 642 hc0_settings_error "There was a problem loading settings, some may have been reset";
CM_ SG_ 642 hc0_maxon_error "error with the maxon";
CM_ SG_ 642 hc0_maxon_warning "warning with the maxon";
CM_ SG_ 642 hc0_maxon_home_fault "fault during homing";
CM_ SG_ 642 hc0_maxon_homed "homed succesfully";
CM_ SG_ 642 hc0_maxon_normal "operating normally";
CM_ SG_ 642 hc0_control_mode "current mode of height control";
CM_ SG_ 642 hc0_code_version "current version of the HC code";
CM_ SG_ 642 hc0_maxon_error_code "current error code of the maxon";
CM_ SG_ 642 hc0_maxon_last_error_code "last error code if it is already cleared";
CM_ BO_ 643 "the height and filtered height of the attached sensor";
CM_ BO_ 644 "maxon position data and other things";
CM_ SG_ 644 hc0_maxon_target_angle "target angle";
CM_ SG_ 644 hc0_maxon_actual_angle "current angle";
CM_ SG_ 644 hc0_maxon_current "current draw";
CM_ SG_ 644 hc0_maxon_rpm "current velocity";
CM_ BO_ 645 "maxon position data and other things";
CM_ SG_ 645 hc0_maxon_target_position "target position";
CM_ SG_ 645 hc0_maxon_actual_position "current position";
CM_ BO_ 647 "the set propotional gains";
CM_ SG_ 647 hc0_P_height "poportional gain for the height";
CM_ SG_ 647 hc0_P_roll "poportional gain for the roll";
CM_ BO_ 648 "the set integral gains";
CM_ SG_ 648 hc0_I_height "integral gain for the height";
CM_ SG_ 648 hc0_I_roll "integral gain for the roll";
CM_ BO_ 649 "the set derivative gains";
CM_ SG_ 649 hc0_D_height "derivative gain for the height";
CM_ SG_ 649 hc0_D_roll "derivative gain for the roll";
CM_ BO_ 650 "pass command to hc node";
CM_ SG_ 650 hc1_command_type "get or set a setting. 0x10 is get, 0x20 is set.";
CM_ SG_ 650 hc1_node_id "node id to change it in.";
CM_ SG_ 650 hc1_setting_length "length ot the message command stuff";
CM_ SG_ 650 hc1_setting_id "settings id to change";
CM_ SG_ 650 hc1_setting_value "new value of the setting if it is set";
CM_ BO_ 651 "pass command to hc node";
CM_ SG_ 651 hc1_command_type_response "get or set a setting. 0x10 is get, 0x20 is set.";
CM_ SG_ 651 hc1_node_id_response "node id to change it in.";
CM_ SG_ 651 hc1_setting_length_response "length ot the message command stuff";
CM_ SG_ 651 hc1_setting_id_response "settings id to change that was specified";
CM_ SG_ 651 hc1_setting_value_response "current value of the setting";
CM_ BO_ 652 "the state of the HC node with errors and problems ";
CM_ SG_ 652 hc1_error "There was an error with HC";
CM_ SG_ 652 hc1_warning "non fatal problem with ";
CM_ SG_ 652 hc1_senix_error "error with the senix";
CM_ SG_ 652 hc1_settings_error "There was a problem loading settings, some may have been reset";
CM_ SG_ 652 hc1_maxon_error "error with the maxon";
CM_ SG_ 652 hc1_maxon_warning "warning with the maxon";
CM_ SG_ 652 hc1_maxon_home_fault "fault during homing";
CM_ SG_ 652 hc1_maxon_homed "homed succesfully";
CM_ SG_ 652 hc1_maxon_normal "operating normally";
CM_ SG_ 652 hc1_control_mode "current mode of height control";
CM_ SG_ 652 hc1_code_version "current version of the HC code";
CM_ SG_ 652 hc1_maxon_error_code "current error code of the maxon";
CM_ SG_ 652 hc1_maxon_last_error_code "last error code if it is already cleared";
CM_ BO_ 653 "the height and filtered height of the attached sensor";
CM_ BO_ 654 "maxon position data and other things";
CM_ SG_ 654 hc1_maxon_target_angle "target angle";
CM_ SG_ 654 hc1_maxon_actual_angle "current angle";
CM_ SG_ 654 hc1_maxon_current "current draw";
CM_ SG_ 654 hc1_maxon_rpm "current velocity";
CM_ BO_ 655 "maxon position data and other things";
CM_ SG_ 655 hc1_maxon_target_position "target position";
CM_ SG_ 655 hc1_maxon_actual_position "current position";
CM_ BO_ 657 "the set propotional gains";
CM_ SG_ 657 hc1_P_height "poportional gain for the height";
CM_ SG_ 657 hc1_P_roll "poportional gain for the roll";
CM_ BO_ 658 "the set integral gains";
CM_ SG_ 658 hc1_I_height "integral gain for the height";
CM_ SG_ 658 hc1_I_roll "integral gain for the roll";
CM_ BO_ 659 "the set derivative gains";
CM_ SG_ 659 hc1_D_height "derivative gain for the height";
CM_ SG_ 659 hc1_D_roll "derivative gain for the roll";
CM_ BO_ 660 "pass command to hc node";
CM_ SG_ 660 hc2_command_type "get or set a setting. 0x10 is get, 0x20 is set.";
CM_ SG_ 660 hc2_node_id "node id to change it in.";
CM_ SG_ 660 hc2_setting_length "length ot the message command stuff";
CM_ SG_ 660 hc2_setting_id "settings id to change";
CM_ SG_ 660 hc2_setting_value "new value of the setting if it is set";
CM_ BO_ 661 "pass command to hc node";
CM_ SG_ 661 hc2_command_type_response "get or set a setting. 0x10 is get, 0x20 is set.";
CM_ SG_ 661 hc2_node_id_response "node id to change it in.";
CM_ SG_ 661 hc2_setting_length_response "length ot the message command stuff";
CM_ SG_ 661 hc2_setting_id_response "settings id to change that was specified";
CM_ SG_ 661 hc2_setting_value_response "current value of the setting";
CM_ BO_ 662 "the state of the HC node with errors and problems ";
CM_ SG_ 662 hc2_error "There was an error with HC";
CM_ SG_ 662 hc2_warning "non fatal problem with ";
CM_ SG_ 662 hc2_senix_error "error with the senix";
CM_ SG_ 662 hc2_settings_error "There was a problem loading settings, some may have been reset";
CM_ SG_ 662 hc2_maxon_error "error with the maxon";
CM_ SG_ 662 hc2_maxon_warning "warning with the maxon";
CM_ SG_ 662 hc2_maxon_home_fault "fault during homing";
CM_ SG_ 662 hc2_maxon_homed "homed succesfully";
CM_ SG_ 662 hc2_maxon_normal "operating normally";
CM_ SG_ 662 hc2_control_mode "current mode of height control";
CM_ SG_ 662 hc2_code_version "current version of the HC code";
CM_ SG_ 662 hc2_maxon_error_code "current error code of the maxon";
CM_ SG_ 662 hc2_maxon_last_error_code "last error code if it is already cleared";
CM_ BO_ 663 "the height and filtered height of the attached sensor";
CM_ BO_ 664 "maxon position data and other things";
CM_ SG_ 664 hc2_maxon_target_angle "target angle";
CM_ SG_ 664 hc2_maxon_actual_angle "current angle";
CM_ SG_ 664 hc2_maxon_current "current draw";
CM_ SG_ 664 hc2_maxon_rpm "current velocity";
CM_ BO_ 665 "maxon position data and other things";
CM_ SG_ 665 hc2_maxon_target_position "target position";
CM_ SG_ 665 hc2_maxon_actual_position "current position";
CM_ BO_ 667 "the set propotional gains";
CM_ SG_ 667 hc2_P_height "poportional gain for the height";
CM_ SG_ 667 hc2_P_roll "poportional gain for the roll";
CM_ BO_ 668 "the set integral gains";
CM_ SG_ 668 hc2_I_height "integral gain for the height";
CM_ SG_ 668 hc2_I_roll "integral gain for the roll";
CM_ BO_ 669 "the set derivative gains";
CM_ SG_ 669 hc2_D_height "derivative gain for the height";
CM_ SG_ 669 hc2_D_roll "derivative gain for the roll";
CM_ BO_ 670 "pass command to hc node";
CM_ SG_ 670 hc3_command_type "get or set a setting. 0x10 is get, 0x20 is set.";
CM_ SG_ 670 hc3_node_id "node id to change it in.";
CM_ SG_ 670 hc3_setting_length "length ot the message command stuff";
CM_ SG_ 670 hc3_setting_id "settings id to change";
CM_ SG_ 670 hc3_setting_value "new value of the setting if it is set";
CM_ BO_ 671 "pass command to hc node";
CM_ SG_ 671 hc3_command_type_response "get or set a setting. 0x10 is get, 0x20 is set.";
CM_ SG_ 671 hc3_node_id_response "node id to change it in.";
CM_ SG_ 671 hc3_setting_length_response "length ot the message command stuff";
CM_ SG_ 671 hc3_setting_id_response "settings id to change that was specified";
CM_ SG_ 671 hc3_setting_value_response "current value of the setting";
CM_ BO_ 672 "the state of the HC node with errors and problems ";
CM_ SG_ 672 hc3_error "There was an error with HC";
CM_ SG_ 672 hc3_warning "non fatal problem with ";
CM_ SG_ 672 hc3_senix_error "error with the senix";
CM_ SG_ 672 hc3_settings_error "There was a problem loading settings, some may have been reset";
CM_ SG_ 672 hc3_maxon_error "error with the maxon";
CM_ SG_ 672 hc3_maxon_warning "warning with the maxon";
CM_ SG_ 672 hc3_maxon_home_fault "fault during homing";
CM_ SG_ 672 hc3_maxon_homed "homed succesfully";
CM_ SG_ 672 hc3_maxon_normal "operating normally";
CM_ SG_ 672 hc3_control_mode "current mode of height control";
CM_ SG_ 672 hc3_code_version "current version of the HC code";
CM_ SG_ 672 hc3_maxon_error_code "current error code of the maxon";
CM_ SG_ 672 hc3_maxon_last_error_code "last error code if it is already cleared";
CM_ BO_ 673 "the height and filtered height of the attached sensor";
CM_ BO_ 674 "maxon position data and other things";
CM_ SG_ 674 hc3_maxon_target_angle "target angle";
CM_ SG_ 674 hc3_maxon_actual_angle "current angle";
CM_ SG_ 674 hc3_maxon_current "current draw";
CM_ SG_ 674 hc3_maxon_rpm "current velocity";
CM_ BO_ 675 "maxon position data and other things";
CM_ SG_ 675 hc3_maxon_target_position "target position";
CM_ SG_ 675 hc3_maxon_actual_position "current position";
CM_ BO_ 677 "the set propotional gains";
CM_ SG_ 677 hc3_P_height "poportional gain for the height";
CM_ SG_ 677 hc3_P_roll "poportional gain for the roll";
CM_ BO_ 678 "the set integral gains";
CM_ SG_ 678 hc3_I_height "integral gain for the height";
CM_ SG_ 678 hc3_I_roll "integral gain for the roll";
CM_ BO_ 679 "the set derivative gains";
CM_ SG_ 679 hc3_D_height "derivative gain for the height";
CM_ SG_ 679 hc3_D_roll "derivative gain for the roll";
CM_ BO_ 809 "Longitude and latitude coordinates of the boat";
CM_ SG_ 705 FC_Faults_UnderV "Stack Under Voltage Fault";
CM_ SG_ 705 FC_Faults_OverTemo "Coolant Over-Temperature Fault";
CM_ SG_ 705 FC_Faults_HearthBeat "Command Heart Beat Fault";
CM_ SG_ 705 FC_Faults_Estop "Internal System Estop Fault";
CM_ SG_ 705 FC_Faults_LeakCheck "Leak Check Failed Fault";
CM_ SG_ 705 FC_Faults_FreezeMode "Freeze Mode Fault";
CM_ SG_ 705 FC_Faults_CoolFlow "Coolant Low Flow Fault";
CM_ SG_ 705 FC_Faults_Idle "Idle Fault";
CM_ SG_ 705 FC_Faults_AnPurge "Anode Purge Fault";
CM_ SG_ 705 FC_Faults_StkCurrent "Stack Current Fault";
CM_ SG_ 705 FC_Faults_H2_Opressure "H2 Supply Over Pressure Fault";
CM_ SG_ 705 FC_Faults_H2_Upressure "H2 Supply Under Pressure Fault";
CM_ SG_ 705 FC_Alarms_H2_PSensRange "H2 Pressure Sensor Out of Range Alarm";
CM_ SG_ 705 FC_Alarms_AirFlowRange "Air Flow Out of Range Alarm";
CM_ SG_ 705 FC_Alarms_CsenseRange "Current Sensor Out of Range Alarm";
CM_ SG_ 705 FC_Alarms_CoolTempHigh "Coolant Temperature High Alarm";
CM_ SG_ 705 FC_Alarms_OverPower "System Over-Power Alarm";
CM_ SG_ 705 FC_Alarms_NonRun "Air Flow in a Non-Run State Alarm";
CM_ SG_ 705 FC_Alarms_BlowFlow "Blower Low Flow Alarm";
CM_ SG_ 705 FC_Alarms_AnPumpSpeed "Anode Pump Over/Under Speed Alarm";
CM_ SG_ 705 FC_Alarms_CoolTemp "Coolant Temp. Out of Range Alarm";
CM_ SG_ 705 FC_Alarms_BlowVoltLow "Blower Low Voltage Alarm";
CM_ SG_ 705 FC_Alarms_Recovery "Recovery Alarm";
CM_ SG_ 705 FC_Alarms_CoolFlow "Coolant Low Flow Alarm";
CM_ SG_ 705 FC_StackLowC "Stack Low Current Alarm";
CM_ SG_ 705 FC_Alarms_eFCVM_Finger "eFCVM Bad Finger Alarm";
CM_ SG_ 705 FC_Alarms_EEPROM "EEPROM Error Alarm";
CM_ SG_ 705 FC_Alarms_EMP_Pump "EMP Pump Alarm";
CM_ SG_ 801 Xsense_FilterMode "Mask for the 3 bit filter mode field. Values: 0 false 1 true ";
CM_ SG_ 801 HaveGnssTimePulse "Indicates that the 1PPS GNSS time pulse is present. Values: 0 false 1 true ";
CM_ SG_ 801 ClipMagZ "Indicates if there was clipping on the Z-axis of the magnetometer. Values: 0 false 1 true ";
CM_ SG_ 801 Retransmitted "When set Indicates the sample was received as a retransmission. Values: 0 false 1 true ";
CM_ SG_ 801 ClippingDetected "When set Indicates clipping has occurred. Values: 0 false 1 true ";
CM_ SG_ 801 Interpolated "When set Indicates the sample is an interpolation between other samples. Values: 0 false 1 true ";
CM_ SG_ 801 SyncIn "When set indicates a sync-in event has been triggered. Values: 0 false 1 true ";
CM_ SG_ 801 SyncOut "When set Indicates a sync-out event has been generated. Values: 0 false 1 true ";
CM_ SG_ 801 ClipAccX "Indicates if there was clipping on the X-axis of the accelerometer. Values: 0 false 1 true ";
CM_ SG_ 801 ClipAccY "Indicates if there was clipping on the Y-axis of the accelerometer. Values: 0 false 1 true ";
CM_ SG_ 801 ClipAccZ "Indicates if there was clipping on the Z-axis of the accelerometer. Values: 0 false 1 true ";
CM_ SG_ 801 ClipGyrX "Indicates if there was clipping on the X-axis of the gyroscope. Values: 0 false 1 true ";
CM_ SG_ 801 ClipGyrY "Indicates if there was clipping on the Y-axis of the gyroscope. Values: 0 false 1 true ";
CM_ SG_ 801 ClipGyrZ "Indicates if there was clipping on the Z-axis of the gyroscope. Values: 0 false 1 true ";
CM_ SG_ 801 ClipMagX "Indicates if there was clipping on the X-axis of the magnetometer. Values: 0 false 1 true ";
CM_ SG_ 801 ClipMagY "Indicates if there was clipping on the Y-axis of the magnetometer. Values: 0 false 1 true ";
CM_ SG_ 801 SelfTestOk "Set when the self test result was ok. Values: 0 false 1 true ";
CM_ SG_ 801 Xsense_RtkStatus "Mask for 2 bit RTK status field. Values: 0 No RTK 1 RTK floating 2 RTK fixed ";
CM_ SG_ 801 OrientationValid "Set when the computed orientation is valid. The orientation may be invalid during startup or when the Xsens_Sensor data is clipping during violent (for the device) motion. Values: 0 false 1 true ";
CM_ SG_ 801 GpsValid "Set when the device has a GPS receiver and the receiver says that there is a GPS position fix.. Values: 0 false 1 true ";
CM_ SG_ 801 RepresentativeMotion "Indicates if the In-Run Compass Calibration is doing the representative motion analysis. Values: 0 false 1 true ";
CM_ SG_ 801 ExternalClockSynced "Indicates whether the internal clock is synced with an external clock (Either GNNS or custom provided clock sync). Values: 0 false 1 true ";
CM_ SG_ 801 Xsense_NoRotation "Values: 1 Aborted 2 SamplesRejected 3 RunningNormally ";
CM_ BO_ 833 "Coolant Temperature Transmission from the PDC";
CM_ SG_ 1400 BMS_Overall_NumbOfCellsMSB "Add MSB and LSB to get total";
CM_ SG_ 1400 BMS_Overall_NumbOfCellsLSB "Add MSB and LSB to get total";
CM_ SG_ 1401 BMS_Voltage_TotalVbyte2 "Add all bytes to get total";
CM_ SG_ 1401 BMS_Voltage_TotalVbyte3 "Add all bytes to get total";
CM_ SG_ 1401 BMS_Voltage_TotalVbyte0 "Add all bytes to get total";
CM_ SG_ 1401 BMS_Voltage_TotalVbyte1 "Add all bytes to get total";
CM_ BO_ 1 "current command to the DCDC";
CM_ BU_ imc_BUSFX_2_133754 "Serial number: 133754
Slot number: 1
Node number: 1";

BA_DEF_ BO_ "GenMsgCycleTimeus" INT 100 60000000;

BA_DEF_DEF_  "GenMsgCycleTimeus" 100000;

BA_ "GenMsgCycleTimeus" BO_ 16 10000;
BA_ "GenMsgCycleTimeus" BO_ 17 200000;
BA_ "GenMsgCycleTimeus" BO_ 18 200000;
BA_ "GenMsgCycleTimeus" BO_ 19 200000;
BA_ "GenMsgCycleTimeus" BO_ 577 200000;
BA_ "GenMsgCycleTimeus" BO_ 833 200000;
BA_ "GenMsgCycleTimeus" BO_ 1313 10000;
